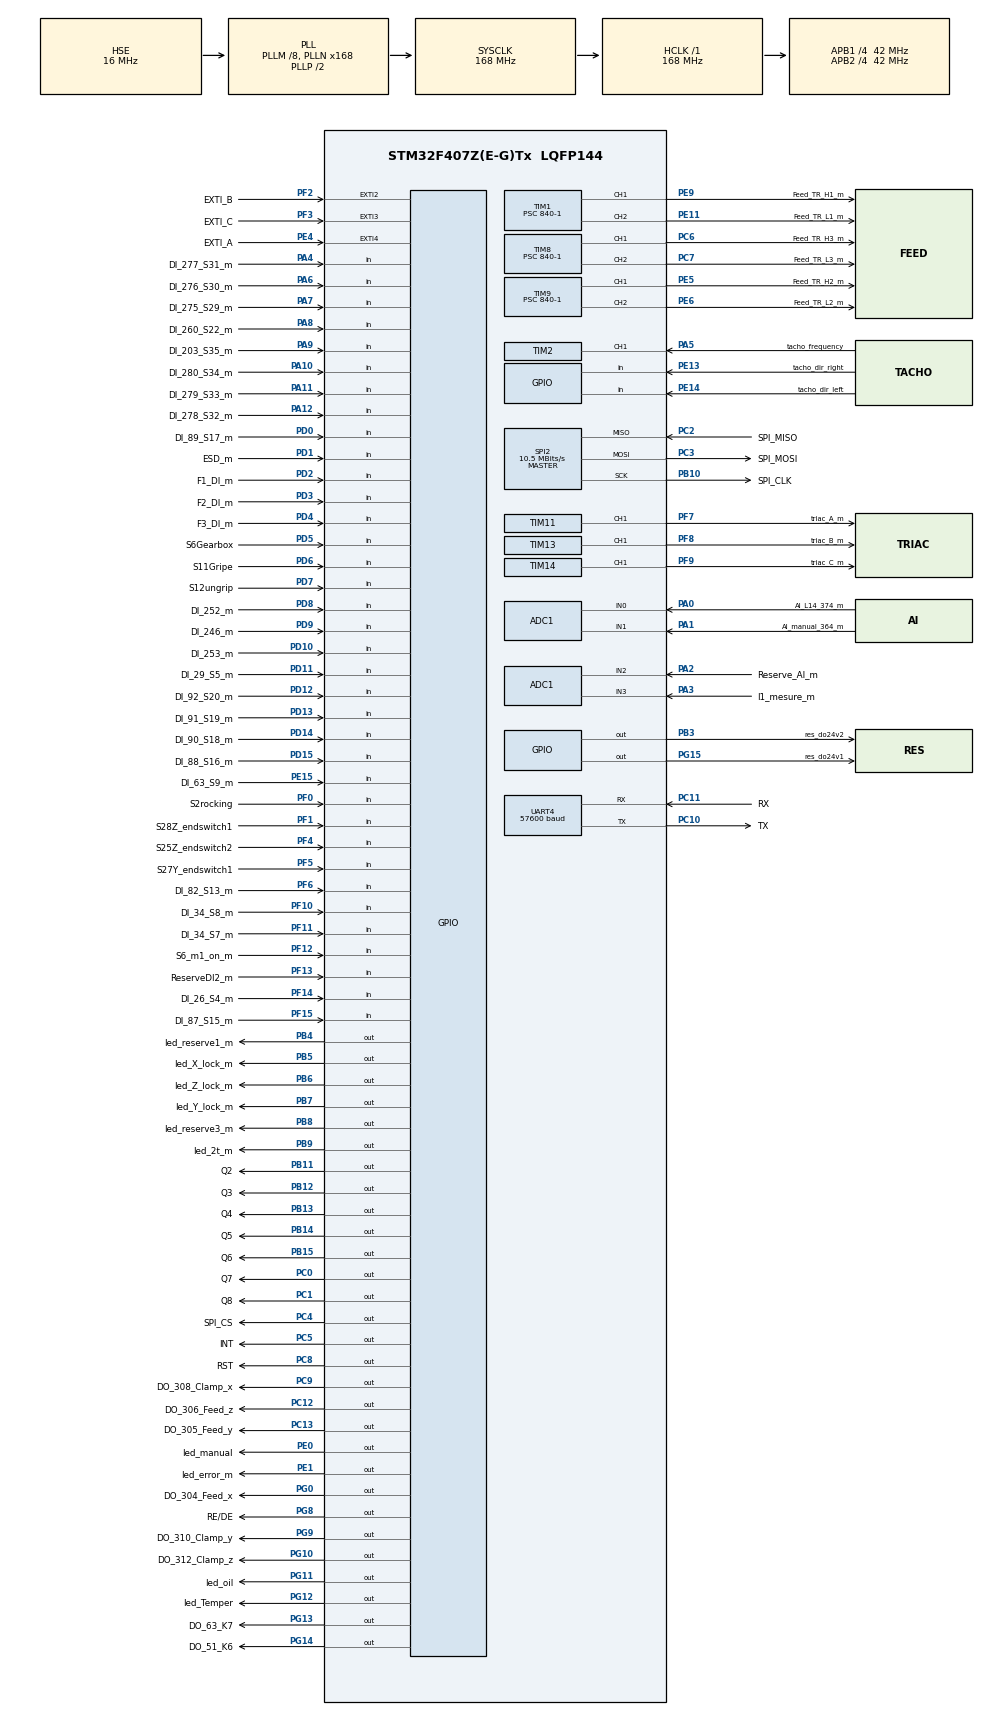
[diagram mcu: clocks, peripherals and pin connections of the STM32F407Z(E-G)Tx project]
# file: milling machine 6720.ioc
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ADC1.Channel-0\#ChannelRegularConversion=ADC_CHANNEL_0
ADC1.Channel-1\#ChannelRegularConversion=ADC_CHANNEL_0
ADC1.Channel-2\#ChannelRegularConversion=ADC_CHANNEL_0
ADC1.Channel-3\#ChannelRegularConversion=ADC_CHANNEL_0
ADC1.EOCSelection=ADC_EOC_SEQ_CONV
ADC1.InjNumberOfConversion=0
ADC1.NbrOfConversion=4
ADC1.NbrOfConversionFlag=1
ADC1.Rank-0\#ChannelRegularConversion=1
ADC1.Rank-1\#ChannelRegularConversion=2
ADC1.Rank-2\#ChannelRegularConversion=3
ADC1.Rank-3\#ChannelRegularConversion=4
ADC1.SamplingTime-0\#ChannelRegularConversion=ADC_SAMPLETIME_84CYCLES
ADC1.SamplingTime-1\#ChannelRegularConversion=ADC_SAMPLETIME_84CYCLES
ADC1.SamplingTime-2\#ChannelRegularConversion=ADC_SAMPLETIME_84CYCLES
ADC1.SamplingTime-3\#ChannelRegularConversion=ADC_SAMPLETIME_84CYCLES
ADC1.ScanConvMode=ENABLE
ADC1.master=1
Dma.ADC1.0.Direction=DMA_PERIPH_TO_MEMORY
Dma.ADC1.0.FIFOMode=DMA_FIFOMODE_DISABLE
Dma.ADC1.0.Instance=DMA2_Stream0
Dma.ADC1.0.MemDataAlignment=DMA_MDATAALIGN_HALFWORD
Dma.ADC1.0.MemInc=DMA_MINC_ENABLE
Dma.ADC1.0.Mode=DMA_NORMAL
Dma.ADC1.0.PeriphDataAlignment=DMA_PDATAALIGN_HALFWORD
Dma.ADC1.0.PeriphInc=DMA_PINC_DISABLE
Dma.ADC1.0.Priority=DMA_PRIORITY_LOW
Dma.Request0=ADC1
Dma.Request1=UART4_RX
Dma.Request2=UART4_TX
Dma.UART4_RX.1.Direction=DMA_PERIPH_TO_MEMORY
Dma.UART4_RX.1.FIFOMode=DMA_FIFOMODE_DISABLE
Dma.UART4_RX.1.Instance=DMA1_Stream2
Dma.UART4_RX.1.MemDataAlignment=DMA_MDATAALIGN_BYTE
Dma.UART4_RX.1.MemInc=DMA_MINC_ENABLE
Dma.UART4_RX.1.Mode=DMA_NORMAL
Dma.UART4_RX.1.PeriphDataAlignment=DMA_PDATAALIGN_BYTE
Dma.UART4_RX.1.PeriphInc=DMA_PINC_DISABLE
Dma.UART4_RX.1.Priority=DMA_PRIORITY_LOW
Dma.UART4_TX.2.Direction=DMA_MEMORY_TO_PERIPH
Dma.UART4_TX.2.FIFOMode=DMA_FIFOMODE_DISABLE
Dma.UART4_TX.2.Instance=DMA1_Stream4
Dma.UART4_TX.2.MemDataAlignment=DMA_MDATAALIGN_BYTE
Dma.UART4_TX.2.MemInc=DMA_MINC_ENABLE
Dma.UART4_TX.2.Mode=DMA_NORMAL
Dma.UART4_TX.2.PeriphDataAlignment=DMA_PDATAALIGN_BYTE
Dma.UART4_TX.2.PeriphInc=DMA_PINC_DISABLE
Dma.UART4_TX.2.Priority=DMA_PRIORITY_LOW
FREERTOS.Tasks01=MainTask,24,1024,StartMainTask,Default,NULL,Dynamic,NULL,NULL;Comunication,19,512,StartComunication,Default,NULL,Dynamic,NULL,NULL;feed,24,512,StartFeed,Default,NULL,Dynamic,NULL,NULL
IWDG.Prescaler=IWDG_PRESCALER_256
Mcu.Family=STM32F4
Mcu.Name=STM32F407Z(E-G)Tx
Mcu.Package=LQFP144
NVIC.DMA1_Stream2_IRQn=true\:5\:0\:false\:false\:true\:true\:false\:true\:true
NVIC.DMA1_Stream4_IRQn=true\:5\:0\:false\:false\:true\:true\:false\:true\:true
NVIC.DMA2_Stream0_IRQn=true\:5\:0\:false\:false\:true\:true\:false\:true\:true
NVIC.PriorityGroup=NVIC_PRIORITYGROUP_4
NVIC.TIM2_IRQn=true\:5\:0\:false\:false\:true\:true\:true\:true\:true
NVIC.TIM6_DAC_IRQn=true\:15\:0\:false\:false\:true\:false\:false\:true\:true
NVIC.TimeBase=TIM6_DAC_IRQn
NVIC.TimeBaseIP=TIM6
PA0-WKUP.GPIO_Label=AI_L14_374_m
PA0-WKUP.Signal=ADCx_IN0
PA1.GPIO_Label=AI_manual_364_m
PA1.Signal=ADCx_IN1
PA10.GPIO_Label=DI_280_S34_m
PA10.Signal=GPIO_Input
PA11.GPIO_Label=DI_279_S33_m
PA11.Signal=GPIO_Input
PA12.GPIO_Label=DI_278_S32_m
PA12.Signal=GPIO_Input
PA13.Mode=Serial_Wire
PA13.Signal=SYS_JTMS-SWDIO
PA14.Mode=Serial_Wire
PA14.Signal=SYS_JTCK-SWCLK
PA2.GPIO_Label=Reserve_AI_m
PA2.Signal=ADCx_IN2
PA3.GPIO_Label=I1_mesure_m
PA3.Signal=ADCx_IN3
PA4.GPIO_Label=DI_277_S31_m
PA4.Signal=GPIO_Input
PA5.GPIO_Label=tacho_frequency
PA5.Signal=S_TIM2_CH1_ETR
PA6.GPIO_Label=DI_276_S30_m
PA6.Signal=GPIO_Input
PA7.GPIO_Label=DI_275_S29_m
PA7.Signal=GPIO_Input
PA8.GPIO_Label=DI_260_S22_m
PA8.Signal=GPIO_Input
PA9.GPIO_Label=DI_203_S35_m
PA9.Signal=GPIO_Input
PB10.GPIO_Label=SPI_CLK
PB10.Mode=Full_Duplex_Master
PB10.Signal=SPI2_SCK
PB11.GPIO_Label=Q2
PB11.GPIO_ModeDefaultOutputPP=GPIO_MODE_OUTPUT_OD
PB11.GPIO_PuPd=GPIO_NOPULL
PB11.PinState=GPIO_PIN_SET
PB11.Signal=GPIO_Output
PB12.GPIO_Label=Q3
PB12.GPIO_ModeDefaultOutputPP=GPIO_MODE_OUTPUT_OD
PB12.GPIO_PuPd=GPIO_NOPULL
PB12.PinState=GPIO_PIN_SET
PB12.Signal=GPIO_Output
PB13.GPIO_Label=Q4
PB13.GPIO_ModeDefaultOutputPP=GPIO_MODE_OUTPUT_OD
PB13.GPIO_PuPd=GPIO_NOPULL
PB13.PinState=GPIO_PIN_SET
PB13.Signal=GPIO_Output
PB14.GPIO_Label=Q5
PB14.GPIO_ModeDefaultOutputPP=GPIO_MODE_OUTPUT_OD
PB14.GPIO_PuPd=GPIO_NOPULL
PB14.PinState=GPIO_PIN_SET
PB14.Signal=GPIO_Output
PB15.GPIO_Label=Q6
PB15.GPIO_ModeDefaultOutputPP=GPIO_MODE_OUTPUT_OD
PB15.GPIO_PuPd=GPIO_NOPULL
PB15.PinState=GPIO_PIN_SET
PB15.Signal=GPIO_Output
PB3.GPIO_Label=res_do24v2
PB3.GPIO_ModeDefaultOutputPP=GPIO_MODE_OUTPUT_OD
PB3.GPIO_PuPd=GPIO_NOPULL
PB3.PinState=GPIO_PIN_SET
PB3.Signal=GPIO_Output
PB4.GPIO_Label=led_reserve1_m
PB4.GPIO_ModeDefaultOutputPP=GPIO_MODE_OUTPUT_OD
PB4.GPIO_PuPd=GPIO_NOPULL
PB4.PinState=GPIO_PIN_SET
PB4.Signal=GPIO_Output
PB5.GPIO_Label=led_X_lock_m
PB5.GPIO_ModeDefaultOutputPP=GPIO_MODE_OUTPUT_OD
PB5.GPIO_PuPd=GPIO_NOPULL
PB5.PinState=GPIO_PIN_SET
PB5.Signal=GPIO_Output
PB6.GPIO_Label=led_Z_lock_m
PB6.GPIO_ModeDefaultOutputPP=GPIO_MODE_OUTPUT_OD
PB6.GPIO_PuPd=GPIO_NOPULL
PB6.PinState=GPIO_PIN_SET
PB6.Signal=GPIO_Output
PB7.GPIO_Label=led_Y_lock_m
PB7.GPIO_ModeDefaultOutputPP=GPIO_MODE_OUTPUT_OD
PB7.GPIO_PuPd=GPIO_NOPULL
PB7.PinState=GPIO_PIN_SET
PB7.Signal=GPIO_Output
PB8.GPIO_Label=led_reserve3_m
PB8.GPIO_ModeDefaultOutputPP=GPIO_MODE_OUTPUT_OD
PB8.GPIO_PuPd=GPIO_NOPULL
PB8.PinState=GPIO_PIN_SET
PB8.Signal=GPIO_Output
PB9.GPIO_Label=led_2t_m
PB9.GPIO_ModeDefaultOutputPP=GPIO_MODE_OUTPUT_OD
PB9.GPIO_PuPd=GPIO_NOPULL
PB9.PinState=GPIO_PIN_SET
PB9.Signal=GPIO_Output
PC0.GPIO_Label=Q7
PC0.GPIO_ModeDefaultOutputPP=GPIO_MODE_OUTPUT_OD
PC0.GPIO_PuPd=GPIO_NOPULL
PC0.PinState=GPIO_PIN_SET
PC0.Signal=GPIO_Output
PC1.GPIO_Label=Q8
PC1.GPIO_ModeDefaultOutputPP=GPIO_MODE_OUTPUT_OD
PC1.GPIO_PuPd=GPIO_NOPULL
PC1.PinState=GPIO_PIN_SET
PC1.Signal=GPIO_Output
PC10.GPIO_Label=TX
PC10.Mode=Asynchronous
PC10.Signal=UART4_TX
PC11.GPIO_Label=RX
PC11.Mode=Asynchronous
PC11.Signal=UART4_RX
PC12.GPIO_Label=DO_306_Feed_z
PC12.GPIO_ModeDefaultOutputPP=GPIO_MODE_OUTPUT_OD
PC12.GPIO_PuPd=GPIO_NOPULL
PC12.PinState=GPIO_PIN_SET
PC12.Signal=GPIO_Output
PC13-ANTI_TAMP.GPIO_Label=DO_305_Feed_y
PC13-ANTI_TAMP.GPIO_ModeDefaultOutputPP=GPIO_MODE_OUTPUT_OD
PC13-ANTI_TAMP.GPIO_PuPd=GPIO_NOPULL
PC13-ANTI_TAMP.PinState=GPIO_PIN_SET
PC13-ANTI_TAMP.Signal=GPIO_Output
PC2.GPIO_Label=SPI_MISO
PC2.Mode=Full_Duplex_Master
PC2.Signal=SPI2_MISO
PC3.GPIO_Label=SPI_MOSI
PC3.Mode=Full_Duplex_Master
PC3.Signal=SPI2_MOSI
PC4.GPIO_Label=SPI_CS
PC4.PinState=GPIO_PIN_RESET
PC4.Signal=GPIO_Output
PC5.GPIO_Label=INT
PC5.PinState=GPIO_PIN_RESET
PC5.Signal=GPIO_Output
PC6.GPIO_Label=Feed_TR_H3_m
PC6.Signal=S_TIM8_CH1
PC7.GPIO_Label=Feed_TR_L3_m
PC7.Signal=S_TIM8_CH2
PC8.GPIO_Label=RST
PC8.PinState=GPIO_PIN_RESET
PC8.Signal=GPIO_Output
PC9.GPIO_Label=DO_308_Clamp_x
PC9.GPIO_ModeDefaultOutputPP=GPIO_MODE_OUTPUT_OD
PC9.GPIO_PuPd=GPIO_NOPULL
PC9.PinState=GPIO_PIN_SET
PC9.Signal=GPIO_Output
PD0.GPIO_Label=DI_89_S17_m
PD0.Signal=GPIO_Input
PD1.GPIO_Label=ESD_m
PD1.Signal=GPIO_Input
PD10.GPIO_Label=DI_253_m
PD10.Signal=GPIO_Input
PD11.GPIO_Label=DI_29_S5_m
PD11.Signal=GPIO_Input
PD12.GPIO_Label=DI_92_S20_m
PD12.Signal=GPIO_Input
PD13.GPIO_Label=DI_91_S19_m
PD13.Signal=GPIO_Input
PD14.GPIO_Label=DI_90_S18_m
PD14.Signal=GPIO_Input
PD15.GPIO_Label=DI_88_S16_m
PD15.Signal=GPIO_Input
PD2.GPIO_Label=F1_DI_m
PD2.Signal=GPIO_Input
PD3.GPIO_Label=F2_DI_m
PD3.Signal=GPIO_Input
PD4.GPIO_Label=F3_DI_m
PD4.Signal=GPIO_Input
PD5.GPIO_Label=S6Gearbox
PD5.Signal=GPIO_Input
PD6.GPIO_Label=S11Gripe
PD6.Signal=GPIO_Input
PD7.GPIO_Label=S12ungrip
PD7.GPIO_PuPd=GPIO_NOPULL
PD7.Signal=GPIO_Input
PD8.GPIO_Label=DI_252_m
PD8.Signal=GPIO_Input
PD9.GPIO_Label=DI_246_m
PD9.Signal=GPIO_Input
PE0.GPIO_Label=led_manual
PE0.GPIO_ModeDefaultOutputPP=GPIO_MODE_OUTPUT_OD
PE0.PinState=GPIO_PIN_SET
PE0.Signal=GPIO_Output
PE1.GPIO_Label=led_error_m
PE1.GPIO_ModeDefaultOutputPP=GPIO_MODE_OUTPUT_OD
PE1.GPIO_PuPd=GPIO_NOPULL
PE1.PinState=GPIO_PIN_SET
PE1.Signal=GPIO_Output
PE11.GPIO_Label=Feed_TR_L1_m
PE11.Signal=S_TIM1_CH2
PE13.GPIO_Label=tacho_dir_right
PE13.Signal=GPIO_Input
PE14.GPIO_Label=tacho_dir_left
PE14.Signal=GPIO_Input
PE15.GPIO_Label=DI_63_S9_m
PE15.Signal=GPIO_Input
PE4.GPIO_Label=EXTI_A
PE4.Signal=GPXTI4
PE5.GPIO_Label=Feed_TR_H2_m
PE5.Signal=S_TIM9_CH1
PE6.GPIO_Label=Feed_TR_L2_m
PE6.Signal=S_TIM9_CH2
PE9.GPIO_Label=Feed_TR_H1_m
PE9.Signal=S_TIM1_CH1
PF0.GPIO_Label=S2rocking
PF0.Signal=GPIO_Input
PF1.GPIO_Label=S28Z_endswitch1
PF1.Signal=GPIO_Input
PF10.GPIO_Label=DI_34_S8_m
PF10.Signal=GPIO_Input
PF11.GPIO_Label=DI_34_S7_m
PF11.Signal=GPIO_Input
PF12.GPIO_Label=S6_m1_on_m
PF12.Signal=GPIO_Input
PF13.GPIO_Label=ReserveDI2_m
PF13.Signal=GPIO_Input
PF14.GPIO_Label=DI_26_S4_m
PF14.Signal=GPIO_Input
PF15.GPIO_Label=DI_87_S15_m
PF15.Signal=GPIO_Input
PF2.GPIO_Label=EXTI_B
PF2.GPIO_ModeDefaultEXTI=GPIO_MODE_IT_RISING_FALLING
PF2.Signal=GPXTI2
PF3.GPIO_Label=EXTI_C
PF3.GPIO_ModeDefaultEXTI=GPIO_MODE_IT_RISING_FALLING
PF3.Signal=GPXTI3
PF4.GPIO_Label=S25Z_endswitch2
PF4.Signal=GPIO_Input
PF5.GPIO_Label=S27Y_endswitch1
PF5.Signal=GPIO_Input
PF6.GPIO_Label=DI_82_S13_m
PF6.Signal=GPIO_Input
PF7.GPIO_Label=triac_A_m
PF7.Signal=S_TIM11_CH1
PF8.GPIO_Label=triac_B_m
PF8.Signal=S_TIM13_CH1
PF9.GPIO_Label=triac_C_m
PF9.Signal=S_TIM14_CH1
PG0.GPIO_Label=DO_304_Feed_x
PG0.GPIO_ModeDefaultOutputPP=GPIO_MODE_OUTPUT_OD
PG0.GPIO_PuPd=GPIO_NOPULL
PG0.PinState=GPIO_PIN_SET
PG0.Signal=GPIO_Output
PG10.GPIO_Label=DO_312_Clamp_z
PG10.GPIO_ModeDefaultOutputPP=GPIO_MODE_OUTPUT_OD
PG10.GPIO_PuPd=GPIO_NOPULL
PG10.PinState=GPIO_PIN_SET
PG10.Signal=GPIO_Output
PG11.GPIO_Label=led_oil
PG11.GPIO_ModeDefaultOutputPP=GPIO_MODE_OUTPUT_OD
PG11.GPIO_PuPd=GPIO_NOPULL
PG11.PinState=GPIO_PIN_SET
PG11.Signal=GPIO_Output
PG12.GPIO_Label=led_Temper
PG12.GPIO_ModeDefaultOutputPP=GPIO_MODE_OUTPUT_OD
PG12.GPIO_PuPd=GPIO_NOPULL
PG12.PinState=GPIO_PIN_SET
PG12.Signal=GPIO_Output
PG13.GPIO_Label=DO_63_K7
PG13.GPIO_ModeDefaultOutputPP=GPIO_MODE_OUTPUT_OD
PG13.GPIO_PuPd=GPIO_NOPULL
PG13.PinState=GPIO_PIN_SET
PG13.Signal=GPIO_Output
PG14.GPIO_Label=DO_51_K6
PG14.GPIO_ModeDefaultOutputPP=GPIO_MODE_OUTPUT_OD
PG14.GPIO_PuPd=GPIO_NOPULL
PG14.PinState=GPIO_PIN_SET
PG14.Signal=GPIO_Output
PG15.GPIO_Label=res_do24v1
PG15.GPIO_ModeDefaultOutputPP=GPIO_MODE_OUTPUT_OD
PG15.GPIO_PuPd=GPIO_NOPULL
PG15.PinState=GPIO_PIN_SET
PG15.Signal=GPIO_Output
PG8.GPIO_Label=RE/DE
PG8.PinState=GPIO_PIN_RESET
PG8.Signal=GPIO_Output
PG9.GPIO_Label=DO_310_Clamp_y
PG9.GPIO_ModeDefaultOutputPP=GPIO_MODE_OUTPUT_OD
PG9.GPIO_PuPd=GPIO_NOPULL
PG9.PinState=GPIO_PIN_SET
PG9.Signal=GPIO_Output
PH0-OSC_IN.Mode=HSE-External-Oscillator
PH0-OSC_IN.Signal=RCC_OSC_IN
PH1-OSC_OUT.Mode=HSE-External-Oscillator
PH1-OSC_OUT.Signal=RCC_OSC_OUT
ProjectManager.HeapSize=0x200
ProjectManager.StackSize=0x400
ProjectManager.TargetToolchain=EWARM V8
RCC.48MHZClocksFreq_Value=84000000
RCC.AHBFreq_Value=168000000
RCC.APB1CLKDivider=RCC_HCLK_DIV4
RCC.APB1Freq_Value=42000000
RCC.APB1TimFreq_Value=84000000
RCC.APB2CLKDivider=RCC_HCLK_DIV4
RCC.APB2Freq_Value=42000000
RCC.APB2TimFreq_Value=84000000
RCC.CortexFreq_Value=168000000
RCC.HCLKFreq_Value=168000000
RCC.HSE_VALUE=16000000
RCC.HSI_VALUE=16000000
RCC.LSE_VALUE=32768
RCC.PLLM=8
RCC.PLLN=168
RCC.PLLSourceVirtual=RCC_PLLSOURCE_HSE
RCC.SYSCLKFreq_VALUE=168000000
RCC.SYSCLKSource=RCC_SYSCLKSOURCE_PLLCLK
RCC.VCOOutputFreq_Value=336000000
SH.ADCx_IN0.0=ADC1_IN0,IN0
SH.ADCx_IN1.0=ADC1_IN1,IN1
SH.ADCx_IN2.0=ADC1_IN2,IN2
SH.ADCx_IN3.0=ADC1_IN3,IN3
SH.S_TIM11_CH1.0=TIM11_CH1,PWM Generation1 CH1
SH.S_TIM13_CH1.0=TIM13_CH1,PWM Generation1 CH1
SH.S_TIM14_CH1.0=TIM14_CH1,PWM Generation1 CH1
SH.S_TIM1_CH1.0=TIM1_CH1,PWM Generation1 CH1
SH.S_TIM1_CH2.0=TIM1_CH2,PWM Generation2 CH2
SH.S_TIM2_CH1_ETR.0=TIM2_CH1,Input_Capture1_from_TI1
SH.S_TIM8_CH1.0=TIM8_CH1,PWM Generation1 CH1
SH.S_TIM8_CH2.0=TIM8_CH2,PWM Generation2 CH2
SH.S_TIM9_CH1.0=TIM9_CH1,PWM Generation1 CH1
SH.S_TIM9_CH2.0=TIM9_CH2,PWM Generation2 CH2
SPI2.BaudRatePrescaler=SPI_BAUDRATEPRESCALER_4
SPI2.CalculateBaudRate=10.5 MBits/s
SPI2.Direction=SPI_DIRECTION_2LINES
SPI2.Mode=SPI_MODE_MASTER
SPI2.VirtualType=VM_MASTER
TIM1.Channel-PWM\ Generation1\ CH1=TIM_CHANNEL_1
TIM1.Channel-PWM\ Generation2\ CH2=TIM_CHANNEL_2
TIM1.OCIdleState_1=TIM_OCIDLESTATE_RESET
TIM1.OCIdleState_2=TIM_OCIDLESTATE_RESET
TIM1.OCMode_PWM-PWM\ Generation1\ CH1=TIM_OCMODE_PWM1
TIM1.OCMode_PWM-PWM\ Generation2\ CH2=TIM_OCMODE_PWM1
TIM1.Period=1999
TIM1.Prescaler=840-1
TIM11.Channel=TIM_CHANNEL_1
TIM11.OCMode_PWM=TIM_OCMODE_PWM2
TIM11.Period=999
TIM11.Prescaler=840-1
TIM13.Channel=TIM_CHANNEL_1
TIM13.OCMode_PWM=TIM_OCMODE_PWM2
TIM13.Period=999
TIM13.Prescaler=840-1
TIM14.Channel=TIM_CHANNEL_1
TIM14.OCMode_PWM=TIM_OCMODE_PWM2
TIM14.Period=999
TIM14.Prescaler=840-1
TIM2.Channel-Input_Capture1_from_TI1=TIM_CHANNEL_1
TIM2.ICFilter_CH1=1
TIM2.ICPolarity_CH1=TIM_INPUTCHANNELPOLARITY_FALLING
TIM2.Prescaler=8400-1
TIM3.Prescaler=65534
TIM8.Channel-PWM\ Generation1\ CH1=TIM_CHANNEL_1
TIM8.Channel-PWM\ Generation2\ CH2=TIM_CHANNEL_2
TIM8.OCIdleState_1=TIM_OCIDLESTATE_RESET
TIM8.OCIdleState_2=TIM_OCIDLESTATE_RESET
TIM8.OCMode_PWM-PWM\ Generation1\ CH1=TIM_OCMODE_PWM1
TIM8.OCMode_PWM-PWM\ Generation2\ CH2=TIM_OCMODE_PWM1
TIM8.Period=1999
TIM8.Prescaler=840-1
TIM9.Channel-PWM\ Generation1\ CH1=TIM_CHANNEL_1
TIM9.Channel-PWM\ Generation2\ CH2=TIM_CHANNEL_2
TIM9.OCMode_PWM-PWM\ Generation1\ CH1=TIM_OCMODE_PWM1
TIM9.OCMode_PWM-PWM\ Generation2\ CH2=TIM_OCMODE_PWM1
TIM9.OCPolarity_1=TIM_OCPOLARITY_HIGH
TIM9.OCPolarity_2=TIM_OCPOLARITY_HIGH
TIM9.Period=1999
TIM9.Prescaler=840-1
UART4.BaudRate=57600
UART4.Parity=PARITY_EVEN
UART4.StopBits=UART_STOPBITS_2
UART4.VirtualMode=Asynchronous
VP_FREERTOS_VS_CMSIS_V2.Mode=CMSIS_V2
VP_IWDG_VS_IWDG.Mode=IWDG_Activate
VP_SYS_VS_tim6.Mode=TIM6
VP_TIM11_VS_ClockSourceINT.Mode=Enable_Timer
VP_TIM11_VS_OPM.Mode=OPM_bit
VP_TIM13_VS_ClockSourceINT.Mode=Enable_Timer
VP_TIM13_VS_OPM.Mode=OPM_bit
VP_TIM14_VS_ClockSourceINT.Mode=Enable_Timer
VP_TIM14_VS_OPM.Mode=OPM_bit
VP_TIM1_VS_OPM.Mode=OPM_bit
VP_TIM2_VS_ClockSourceINT.Mode=Internal
VP_TIM3_VS_ClockSourceINT.Mode=Internal
VP_TIM8_VS_OPM.Mode=OPM_bit
VP_TIM9_VS_OPM.Mode=OPM_bit
board=custom

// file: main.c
/* USER CODE BEGIN Header */
/**
  ******************************************************************************
  * @file           : main.c
  * @brief          : Main program body
  ******************************************************************************
  * @attention
  *
  * Copyright (c) 2023 STMicroelectronics.
  * All rights reserved.
  *
  * This software is licensed under terms that can be found in the LICENSE file
  * in the root directory of this software component.
  * If no LICENSE file comes with this software, it is provided AS-IS.
  *
  ******************************************************************************
  */
/* USER CODE END Header */
#include "main.h"
#include "cmsis_os.h"

/* USER CODE BEGIN Includes */
#if Comissioning==1
#include "stdio.h"
#endif
/* USER CODE END Includes */

ADC_HandleTypeDef hadc1;
DMA_HandleTypeDef hdma_adc1;

IWDG_HandleTypeDef hiwdg;

SPI_HandleTypeDef hspi2;

TIM_HandleTypeDef htim1;
TIM_HandleTypeDef htim2;
TIM_HandleTypeDef htim3;
TIM_HandleTypeDef htim8;
TIM_HandleTypeDef htim9;
TIM_HandleTypeDef htim11;
TIM_HandleTypeDef htim13;
TIM_HandleTypeDef htim14;

UART_HandleTypeDef huart4;
DMA_HandleTypeDef hdma_uart4_rx;
DMA_HandleTypeDef hdma_uart4_tx;

/* Definitions for MainTask */
osThreadId_t MainTaskHandle;
const osThreadAttr_t MainTask_attributes = {
  .name = "MainTask",
  .stack_size = 1024 * 4,
  .priority = (osPriority_t) osPriorityNormal,
};
/* Definitions for Comunication */
osThreadId_t ComunicationHandle;
const osThreadAttr_t Comunication_attributes = {
  .name = "Comunication",
  .stack_size = 512 * 4,
  .priority = (osPriority_t) osPriorityBelowNormal3,
};
/* Definitions for feed */
osThreadId_t feedHandle;
const osThreadAttr_t feed_attributes = {
  .name = "feed",
  .stack_size = 512 * 4,
  .priority = (osPriority_t) osPriorityNormal,
};
/* USER CODE BEGIN PV */
//--------my global variables----------//
volatile uint16_t dma[4];
uint8_t error_my=0, feed_motion=0, M1_motion=0, polyarity,first_intrrupt=1; // 0-off 1-rigt, 2-left, 3-Rocking, 4-brake active
uint16_t Time_b=0,Time_c=0, feed_speed_sp=0, I_M4=0;
uint16_t PWM_M1=0; //0-1000
uint16_t PWM_M4=0;//1000 RPS
uint32_t Freq_TIM2=10000;  //10000 is one rpm/sec or 600000 is one rpm/min
//========================================//
/* USER CODE END PV */

void SystemClock_Config(void);
static void MX_GPIO_Init(void);
static void MX_DMA_Init(void);
static void MX_IWDG_Init(void);
static void MX_TIM1_Init(void);
static void MX_TIM8_Init(void);
static void MX_TIM9_Init(void);
static void MX_UART4_Init(void);
static void MX_ADC1_Init(void);
static void MX_TIM11_Init(void);
static void MX_TIM13_Init(void);
static void MX_TIM14_Init(void);
static void MX_SPI2_Init(void);
static void MX_TIM2_Init(void);
static void MX_TIM3_Init(void);
void StartMainTask(void *argument);
void StartComunication(void *argument);
void StartFeed(void *argument);

int main(void)
{

  /* MCU Configuration--------------------------------------------------------*/

  /* Reset of all peripherals, Initializes the Flash interface and the Systick. */
  HAL_Init();

  /* Configure the system clock */
  SystemClock_Config();

  /* Initialize all configured peripherals */
  MX_GPIO_Init();
  MX_DMA_Init();
  MX_IWDG_Init();
  MX_TIM1_Init();
  MX_TIM8_Init();
  MX_TIM9_Init();
  MX_UART4_Init();
  MX_ADC1_Init();
  MX_TIM11_Init();
  MX_TIM13_Init();
  MX_TIM14_Init();
  MX_SPI2_Init();
  MX_TIM2_Init();
  MX_TIM3_Init();

  /* Init scheduler */
  osKernelInitialize();

  /* Create the thread(s) */
  /* creation of MainTask */
  MainTaskHandle = osThreadNew(StartMainTask, NULL, &MainTask_attributes);

  /* creation of Comunication */
  ComunicationHandle = osThreadNew(StartComunication, NULL, &Comunication_attributes);

  /* creation of feed */
  feedHandle = osThreadNew(StartFeed, NULL, &feed_attributes);

  /* Start scheduler */
  osKernelStart();

  /* We should never get here as control is now taken by the scheduler */
  /* Infinite loop */
  while (1)
  {

  }
}

void SystemClock_Config(void)
{
  RCC_OscInitTypeDef RCC_OscInitStruct = {0};
  RCC_ClkInitTypeDef RCC_ClkInitStruct = {0};

  /** Configure the main internal regulator output voltage
  */
  __HAL_RCC_PWR_CLK_ENABLE();
  __HAL_PWR_VOLTAGESCALING_CONFIG(PWR_REGULATOR_VOLTAGE_SCALE1);

  /** Initializes the RCC Oscillators according to the specified parameters
  * in the RCC_OscInitTypeDef structure.
  */
  RCC_OscInitStruct.OscillatorType = RCC_OSCILLATORTYPE_LSI|RCC_OSCILLATORTYPE_HSE;
  RCC_OscInitStruct.HSEState = RCC_HSE_ON;
  RCC_OscInitStruct.LSIState = RCC_LSI_ON;
  RCC_OscInitStruct.PLL.PLLState = RCC_PLL_ON;
  RCC_OscInitStruct.PLL.PLLSource = RCC_PLLSOURCE_HSE;
  RCC_OscInitStruct.PLL.PLLM = 8;
  RCC_OscInitStruct.PLL.PLLN = 168;
  RCC_OscInitStruct.PLL.PLLP = RCC_PLLP_DIV2;
  RCC_OscInitStruct.PLL.PLLQ = 4;
  if (HAL_RCC_OscConfig(&RCC_OscInitStruct) != HAL_OK)
  {
    Error_Handler();
  }

  /** Initializes the CPU, AHB and APB buses clocks
  */
  RCC_ClkInitStruct.ClockType = RCC_CLOCKTYPE_HCLK|RCC_CLOCKTYPE_SYSCLK
                              |RCC_CLOCKTYPE_PCLK1|RCC_CLOCKTYPE_PCLK2;
  RCC_ClkInitStruct.SYSCLKSource = RCC_SYSCLKSOURCE_PLLCLK;
  RCC_ClkInitStruct.AHBCLKDivider = RCC_SYSCLK_DIV1;
  RCC_ClkInitStruct.APB1CLKDivider = RCC_HCLK_DIV4;
  RCC_ClkInitStruct.APB2CLKDivider = RCC_HCLK_DIV4;

  if (HAL_RCC_ClockConfig(&RCC_ClkInitStruct, FLASH_LATENCY_5) != HAL_OK)
  {
    Error_Handler();
  }
}

static void MX_ADC1_Init(void)
{

  ADC_ChannelConfTypeDef sConfig = {0};

  /** Configure the global features of the ADC (Clock, Resolution, Data Alignment and number of conversion)
  */
  hadc1.Instance = ADC1;
  hadc1.Init.ClockPrescaler = ADC_CLOCK_SYNC_PCLK_DIV2;
  hadc1.Init.Resolution = ADC_RESOLUTION_12B;
  hadc1.Init.ScanConvMode = ENABLE;
  hadc1.Init.ContinuousConvMode = DISABLE;
  hadc1.Init.DiscontinuousConvMode = DISABLE;
  hadc1.Init.ExternalTrigConvEdge = ADC_EXTERNALTRIGCONVEDGE_NONE;
  hadc1.Init.ExternalTrigConv = ADC_SOFTWARE_START;
  hadc1.Init.DataAlign = ADC_DATAALIGN_RIGHT;
  hadc1.Init.NbrOfConversion = 4;
  hadc1.Init.DMAContinuousRequests = DISABLE;
  hadc1.Init.EOCSelection = ADC_EOC_SEQ_CONV;
  if (HAL_ADC_Init(&hadc1) != HAL_OK)
  {
    Error_Handler();
  }

  /** Configure for the selected ADC regular channel its corresponding rank in the sequencer and its sample time.
  */
  sConfig.Channel = ADC_CHANNEL_0;
  sConfig.Rank = 1;
  sConfig.SamplingTime = ADC_SAMPLETIME_84CYCLES;
  if (HAL_ADC_ConfigChannel(&hadc1, &sConfig) != HAL_OK)
  {
    Error_Handler();
  }

  /** Configure for the selected ADC regular channel its corresponding rank in the sequencer and its sample time.
  */
  sConfig.Rank = 2;
  if (HAL_ADC_ConfigChannel(&hadc1, &sConfig) != HAL_OK)
  {
    Error_Handler();
  }

  /** Configure for the selected ADC regular channel its corresponding rank in the sequencer and its sample time.
  */
  sConfig.Rank = 3;
  if (HAL_ADC_ConfigChannel(&hadc1, &sConfig) != HAL_OK)
  {
    Error_Handler();
  }

  /** Configure for the selected ADC regular channel its corresponding rank in the sequencer and its sample time.
  */
  sConfig.Rank = 4;
  if (HAL_ADC_ConfigChannel(&hadc1, &sConfig) != HAL_OK)
  {
    Error_Handler();
  }

}

static void MX_IWDG_Init(void)
{

  hiwdg.Instance = IWDG;
  hiwdg.Init.Prescaler = IWDG_PRESCALER_256;
  hiwdg.Init.Reload = 4095;
  if (HAL_IWDG_Init(&hiwdg) != HAL_OK)
  {
    Error_Handler();
  }

}

static void MX_SPI2_Init(void)
{

  /* SPI2 parameter configuration*/
  hspi2.Instance = SPI2;
  hspi2.Init.Mode = SPI_MODE_MASTER;
  hspi2.Init.Direction = SPI_DIRECTION_2LINES;
  hspi2.Init.DataSize = SPI_DATASIZE_8BIT;
  hspi2.Init.CLKPolarity = SPI_POLARITY_LOW;
  hspi2.Init.CLKPhase = SPI_PHASE_1EDGE;
  hspi2.Init.NSS = SPI_NSS_SOFT;
  hspi2.Init.BaudRatePrescaler = SPI_BAUDRATEPRESCALER_4;
  hspi2.Init.FirstBit = SPI_FIRSTBIT_MSB;
  hspi2.Init.TIMode = SPI_TIMODE_DISABLE;
  hspi2.Init.CRCCalculation = SPI_CRCCALCULATION_DISABLE;
  hspi2.Init.CRCPolynomial = 10;
  if (HAL_SPI_Init(&hspi2) != HAL_OK)
  {
    Error_Handler();
  }

}

static void MX_TIM1_Init(void)
{

  TIM_MasterConfigTypeDef sMasterConfig = {0};
  TIM_OC_InitTypeDef sConfigOC = {0};
  TIM_BreakDeadTimeConfigTypeDef sBreakDeadTimeConfig = {0};

  htim1.Instance = TIM1;
  htim1.Init.Prescaler = 840-1;
  htim1.Init.CounterMode = TIM_COUNTERMODE_UP;
  htim1.Init.Period = 1999;
  htim1.Init.ClockDivision = TIM_CLOCKDIVISION_DIV1;
  htim1.Init.RepetitionCounter = 0;
  htim1.Init.AutoReloadPreload = TIM_AUTORELOAD_PRELOAD_DISABLE;
  if (HAL_TIM_PWM_Init(&htim1) != HAL_OK)
  {
    Error_Handler();
  }
  if (HAL_TIM_OnePulse_Init(&htim1, TIM_OPMODE_SINGLE) != HAL_OK)
  {
    Error_Handler();
  }
  sMasterConfig.MasterOutputTrigger = TIM_TRGO_RESET;
  sMasterConfig.MasterSlaveMode = TIM_MASTERSLAVEMODE_DISABLE;
  if (HAL_TIMEx_MasterConfigSynchronization(&htim1, &sMasterConfig) != HAL_OK)
  {
    Error_Handler();
  }
  sConfigOC.OCMode = TIM_OCMODE_PWM1;
  sConfigOC.Pulse = 0;
  sConfigOC.OCPolarity = TIM_OCPOLARITY_HIGH;
  sConfigOC.OCNPolarity = TIM_OCNPOLARITY_HIGH;
  sConfigOC.OCFastMode = TIM_OCFAST_DISABLE;
  sConfigOC.OCIdleState = TIM_OCIDLESTATE_RESET;
  sConfigOC.OCNIdleState = TIM_OCNIDLESTATE_RESET;
  if (HAL_TIM_PWM_ConfigChannel(&htim1, &sConfigOC, TIM_CHANNEL_1) != HAL_OK)
  {
    Error_Handler();
  }
  if (HAL_TIM_PWM_ConfigChannel(&htim1, &sConfigOC, TIM_CHANNEL_2) != HAL_OK)
  {
    Error_Handler();
  }
  sBreakDeadTimeConfig.OffStateRunMode = TIM_OSSR_DISABLE;
  sBreakDeadTimeConfig.OffStateIDLEMode = TIM_OSSI_DISABLE;
  sBreakDeadTimeConfig.LockLevel = TIM_LOCKLEVEL_OFF;
  sBreakDeadTimeConfig.DeadTime = 0;
  sBreakDeadTimeConfig.BreakState = TIM_BREAK_DISABLE;
  sBreakDeadTimeConfig.BreakPolarity = TIM_BREAKPOLARITY_HIGH;
  sBreakDeadTimeConfig.AutomaticOutput = TIM_AUTOMATICOUTPUT_DISABLE;
  if (HAL_TIMEx_ConfigBreakDeadTime(&htim1, &sBreakDeadTimeConfig) != HAL_OK)
  {
    Error_Handler();
  }
  HAL_TIM_MspPostInit(&htim1);

}

static void MX_TIM2_Init(void)
{

  TIM_ClockConfigTypeDef sClockSourceConfig = {0};
  TIM_MasterConfigTypeDef sMasterConfig = {0};
  TIM_IC_InitTypeDef sConfigIC = {0};

  htim2.Instance = TIM2;
  htim2.Init.Prescaler = 8400-1;
  htim2.Init.CounterMode = TIM_COUNTERMODE_UP;
  htim2.Init.Period = 4294967295;
  htim2.Init.ClockDivision = TIM_CLOCKDIVISION_DIV1;
  htim2.Init.AutoReloadPreload = TIM_AUTORELOAD_PRELOAD_DISABLE;
  if (HAL_TIM_Base_Init(&htim2) != HAL_OK)
  {
    Error_Handler();
  }
  sClockSourceConfig.ClockSource = TIM_CLOCKSOURCE_INTERNAL;
  if (HAL_TIM_ConfigClockSource(&htim2, &sClockSourceConfig) != HAL_OK)
  {
    Error_Handler();
  }
  if (HAL_TIM_IC_Init(&htim2) != HAL_OK)
  {
    Error_Handler();
  }
  sMasterConfig.MasterOutputTrigger = TIM_TRGO_RESET;
  sMasterConfig.MasterSlaveMode = TIM_MASTERSLAVEMODE_DISABLE;
  if (HAL_TIMEx_MasterConfigSynchronization(&htim2, &sMasterConfig) != HAL_OK)
  {
    Error_Handler();
  }
  sConfigIC.ICPolarity = TIM_INPUTCHANNELPOLARITY_FALLING;
  sConfigIC.ICSelection = TIM_ICSELECTION_DIRECTTI;
  sConfigIC.ICPrescaler = TIM_ICPSC_DIV1;
  sConfigIC.ICFilter = 1;
  if (HAL_TIM_IC_ConfigChannel(&htim2, &sConfigIC, TIM_CHANNEL_1) != HAL_OK)
  {
    Error_Handler();
  }

}

static void MX_TIM3_Init(void)
{

  TIM_ClockConfigTypeDef sClockSourceConfig = {0};
  TIM_MasterConfigTypeDef sMasterConfig = {0};

  htim3.Instance = TIM3;
  htim3.Init.Prescaler = 65534;
  htim3.Init.CounterMode = TIM_COUNTERMODE_UP;
  htim3.Init.Period = 65535;
  htim3.Init.ClockDivision = TIM_CLOCKDIVISION_DIV1;
  htim3.Init.AutoReloadPreload = TIM_AUTORELOAD_PRELOAD_DISABLE;
  if (HAL_TIM_Base_Init(&htim3) != HAL_OK)
  {
    Error_Handler();
  }
  sClockSourceConfig.ClockSource = TIM_CLOCKSOURCE_INTERNAL;
  if (HAL_TIM_ConfigClockSource(&htim3, &sClockSourceConfig) != HAL_OK)
  {
    Error_Handler();
  }
  sMasterConfig.MasterOutputTrigger = TIM_TRGO_RESET;
  sMasterConfig.MasterSlaveMode = TIM_MASTERSLAVEMODE_DISABLE;
  if (HAL_TIMEx_MasterConfigSynchronization(&htim3, &sMasterConfig) != HAL_OK)
  {
    Error_Handler();
  }

}

static void MX_TIM8_Init(void)
{

  TIM_MasterConfigTypeDef sMasterConfig = {0};
  TIM_OC_InitTypeDef sConfigOC = {0};
  TIM_BreakDeadTimeConfigTypeDef sBreakDeadTimeConfig = {0};

  htim8.Instance = TIM8;
  htim8.Init.Prescaler = 840-1;
  htim8.Init.CounterMode = TIM_COUNTERMODE_UP;
  htim8.Init.Period = 1999;
  htim8.Init.ClockDivision = TIM_CLOCKDIVISION_DIV1;
  htim8.Init.RepetitionCounter = 0;
  htim8.Init.AutoReloadPreload = TIM_AUTORELOAD_PRELOAD_DISABLE;
  if (HAL_TIM_PWM_Init(&htim8) != HAL_OK)
  {
    Error_Handler();
  }
  if (HAL_TIM_OnePulse_Init(&htim8, TIM_OPMODE_SINGLE) != HAL_OK)
  {
    Error_Handler();
  }
  sMasterConfig.MasterOutputTrigger = TIM_TRGO_RESET;
  sMasterConfig.MasterSlaveMode = TIM_MASTERSLAVEMODE_DISABLE;
  if (HAL_TIMEx_MasterConfigSynchronization(&htim8, &sMasterConfig) != HAL_OK)
  {
    Error_Handler();
  }
  sConfigOC.OCMode = TIM_OCMODE_PWM1;
  sConfigOC.Pulse = 0;
  sConfigOC.OCPolarity = TIM_OCPOLARITY_HIGH;
  sConfigOC.OCNPolarity = TIM_OCNPOLARITY_HIGH;
  sConfigOC.OCFastMode = TIM_OCFAST_DISABLE;
  sConfigOC.OCIdleState = TIM_OCIDLESTATE_RESET;
  sConfigOC.OCNIdleState = TIM_OCNIDLESTATE_RESET;
  if (HAL_TIM_PWM_ConfigChannel(&htim8, &sConfigOC, TIM_CHANNEL_1) != HAL_OK)
  {
    Error_Handler();
  }
  if (HAL_TIM_PWM_ConfigChannel(&htim8, &sConfigOC, TIM_CHANNEL_2) != HAL_OK)
  {
    Error_Handler();
  }
  sBreakDeadTimeConfig.OffStateRunMode = TIM_OSSR_DISABLE;
  sBreakDeadTimeConfig.OffStateIDLEMode = TIM_OSSI_DISABLE;
  sBreakDeadTimeConfig.LockLevel = TIM_LOCKLEVEL_OFF;
  sBreakDeadTimeConfig.DeadTime = 0;
  sBreakDeadTimeConfig.BreakState = TIM_BREAK_DISABLE;
  sBreakDeadTimeConfig.BreakPolarity = TIM_BREAKPOLARITY_HIGH;
  sBreakDeadTimeConfig.AutomaticOutput = TIM_AUTOMATICOUTPUT_DISABLE;
  if (HAL_TIMEx_ConfigBreakDeadTime(&htim8, &sBreakDeadTimeConfig) != HAL_OK)
  {
    Error_Handler();
  }
  HAL_TIM_MspPostInit(&htim8);

}

static void MX_TIM9_Init(void)
{

  TIM_OC_InitTypeDef sConfigOC = {0};

  htim9.Instance = TIM9;
  htim9.Init.Prescaler = 840-1;
  htim9.Init.CounterMode = TIM_COUNTERMODE_UP;
  htim9.Init.Period = 1999;
  htim9.Init.ClockDivision = TIM_CLOCKDIVISION_DIV1;
  htim9.Init.AutoReloadPreload = TIM_AUTORELOAD_PRELOAD_DISABLE;
  if (HAL_TIM_PWM_Init(&htim9) != HAL_OK)
  {
    Error_Handler();
  }
  if (HAL_TIM_OnePulse_Init(&htim9, TIM_OPMODE_SINGLE) != HAL_OK)
  {
    Error_Handler();
  }
  sConfigOC.OCMode = TIM_OCMODE_PWM1;
  sConfigOC.Pulse = 0;
  sConfigOC.OCPolarity = TIM_OCPOLARITY_HIGH;
  sConfigOC.OCFastMode = TIM_OCFAST_DISABLE;
  if (HAL_TIM_PWM_ConfigChannel(&htim9, &sConfigOC, TIM_CHANNEL_1) != HAL_OK)
  {
    Error_Handler();
  }
  if (HAL_TIM_PWM_ConfigChannel(&htim9, &sConfigOC, TIM_CHANNEL_2) != HAL_OK)
  {
    Error_Handler();
  }
  HAL_TIM_MspPostInit(&htim9);

}

static void MX_TIM11_Init(void)
{

  TIM_OC_InitTypeDef sConfigOC = {0};

  htim11.Instance = TIM11;
  htim11.Init.Prescaler = 840-1;
  htim11.Init.CounterMode = TIM_COUNTERMODE_UP;
  htim11.Init.Period = 999;
  htim11.Init.ClockDivision = TIM_CLOCKDIVISION_DIV1;
  htim11.Init.AutoReloadPreload = TIM_AUTORELOAD_PRELOAD_DISABLE;
  if (HAL_TIM_Base_Init(&htim11) != HAL_OK)
  {
    Error_Handler();
  }
  if (HAL_TIM_PWM_Init(&htim11) != HAL_OK)
  {
    Error_Handler();
  }
  if (HAL_TIM_OnePulse_Init(&htim11, TIM_OPMODE_SINGLE) != HAL_OK)
  {
    Error_Handler();
  }
  sConfigOC.OCMode = TIM_OCMODE_PWM2;
  sConfigOC.Pulse = 0;
  sConfigOC.OCPolarity = TIM_OCPOLARITY_HIGH;
  sConfigOC.OCFastMode = TIM_OCFAST_DISABLE;
  if (HAL_TIM_PWM_ConfigChannel(&htim11, &sConfigOC, TIM_CHANNEL_1) != HAL_OK)
  {
    Error_Handler();
  }
  HAL_TIM_MspPostInit(&htim11);

}

static void MX_TIM13_Init(void)
{

  TIM_OC_InitTypeDef sConfigOC = {0};

  htim13.Instance = TIM13;
  htim13.Init.Prescaler = 840-1;
  htim13.Init.CounterMode = TIM_COUNTERMODE_UP;
  htim13.Init.Period = 999;
  htim13.Init.ClockDivision = TIM_CLOCKDIVISION_DIV1;
  htim13.Init.AutoReloadPreload = TIM_AUTORELOAD_PRELOAD_DISABLE;
  if (HAL_TIM_Base_Init(&htim13) != HAL_OK)
  {
    Error_Handler();
  }
  if (HAL_TIM_PWM_Init(&htim13) != HAL_OK)
  {
    Error_Handler();
  }
  if (HAL_TIM_OnePulse_Init(&htim13, TIM_OPMODE_SINGLE) != HAL_OK)
  {
    Error_Handler();
  }
  sConfigOC.OCMode = TIM_OCMODE_PWM2;
  sConfigOC.Pulse = 0;
  sConfigOC.OCPolarity = TIM_OCPOLARITY_HIGH;
  sConfigOC.OCFastMode = TIM_OCFAST_DISABLE;
  if (HAL_TIM_PWM_ConfigChannel(&htim13, &sConfigOC, TIM_CHANNEL_1) != HAL_OK)
  {
    Error_Handler();
  }
  HAL_TIM_MspPostInit(&htim13);

}

static void MX_TIM14_Init(void)
{

  TIM_OC_InitTypeDef sConfigOC = {0};

  htim14.Instance = TIM14;
  htim14.Init.Prescaler = 840-1;
  htim14.Init.CounterMode = TIM_COUNTERMODE_UP;
  htim14.Init.Period = 999;
  htim14.Init.ClockDivision = TIM_CLOCKDIVISION_DIV1;
  htim14.Init.AutoReloadPreload = TIM_AUTORELOAD_PRELOAD_DISABLE;
  if (HAL_TIM_Base_Init(&htim14) != HAL_OK)
  {
    Error_Handler();
  }
  if (HAL_TIM_PWM_Init(&htim14) != HAL_OK)
  {
    Error_Handler();
  }
  if (HAL_TIM_OnePulse_Init(&htim14, TIM_OPMODE_SINGLE) != HAL_OK)
  {
    Error_Handler();
  }
  sConfigOC.OCMode = TIM_OCMODE_PWM2;
  sConfigOC.Pulse = 0;
  sConfigOC.OCPolarity = TIM_OCPOLARITY_HIGH;
  sConfigOC.OCFastMode = TIM_OCFAST_DISABLE;
  if (HAL_TIM_PWM_ConfigChannel(&htim14, &sConfigOC, TIM_CHANNEL_1) != HAL_OK)
  {
    Error_Handler();
  }
  HAL_TIM_MspPostInit(&htim14);

}

static void MX_UART4_Init(void)
{

  huart4.Instance = UART4;
  huart4.Init.BaudRate = 57600;
  huart4.Init.WordLength = UART_WORDLENGTH_8B;
  huart4.Init.StopBits = UART_STOPBITS_2;
  huart4.Init.Parity = UART_PARITY_EVEN;
  huart4.Init.Mode = UART_MODE_TX_RX;
  huart4.Init.HwFlowCtl = UART_HWCONTROL_NONE;
  huart4.Init.OverSampling = UART_OVERSAMPLING_16;
  if (HAL_UART_Init(&huart4) != HAL_OK)
  {
    Error_Handler();
  }

}

static void MX_DMA_Init(void)
{

  /* DMA controller clock enable */
  __HAL_RCC_DMA2_CLK_ENABLE();
  __HAL_RCC_DMA1_CLK_ENABLE();

  /* DMA interrupt init */
  /* DMA1_Stream2_IRQn interrupt configuration */
  HAL_NVIC_SetPriority(DMA1_Stream2_IRQn, 5, 0);
  HAL_NVIC_EnableIRQ(DMA1_Stream2_IRQn);
  /* DMA1_Stream4_IRQn interrupt configuration */
  HAL_NVIC_SetPriority(DMA1_Stream4_IRQn, 5, 0);
  HAL_NVIC_EnableIRQ(DMA1_Stream4_IRQn);
  /* DMA2_Stream0_IRQn interrupt configuration */
  HAL_NVIC_SetPriority(DMA2_Stream0_IRQn, 5, 0);
  HAL_NVIC_EnableIRQ(DMA2_Stream0_IRQn);

}

static void MX_GPIO_Init(void)
{
  GPIO_InitTypeDef GPIO_InitStruct = {0};

  /* GPIO Ports Clock Enable */
  __HAL_RCC_GPIOE_CLK_ENABLE();
  __HAL_RCC_GPIOC_CLK_ENABLE();
  __HAL_RCC_GPIOF_CLK_ENABLE();
  __HAL_RCC_GPIOH_CLK_ENABLE();
  __HAL_RCC_GPIOA_CLK_ENABLE();
  __HAL_RCC_GPIOB_CLK_ENABLE();
  __HAL_RCC_GPIOG_CLK_ENABLE();
  __HAL_RCC_GPIOD_CLK_ENABLE();

  /*Configure GPIO pin Output Level */
  HAL_GPIO_WritePin(GPIOC, DO_305_Feed_y_Pin|Q7_Pin|Q8_Pin|DO_308_Clamp_x_Pin
                          |DO_306_Feed_z_Pin, GPIO_PIN_SET);

  /*Configure GPIO pin Output Level */
  HAL_GPIO_WritePin(GPIOC, SPI_CS_Pin|INT_Pin|RST_Pin, GPIO_PIN_RESET);

  /*Configure GPIO pin Output Level */
  HAL_GPIO_WritePin(GPIOG, DO_304_Feed_x_Pin|DO_310_Clamp_y_Pin|DO_312_Clamp_z_Pin|led_oil_Pin
                          |led_Temper_Pin|DO_63_K7_Pin|DO_51_K6_Pin|res_do24v1_Pin, GPIO_PIN_SET);

  /*Configure GPIO pin Output Level */
  HAL_GPIO_WritePin(GPIOB, Q2_Pin|Q3_Pin|Q4_Pin|Q5_Pin
                          |Q6_Pin|res_do24v2_Pin|led_reserve1_m_Pin|led_X_lock_m_Pin
                          |led_Z_lock_m_Pin|led_Y_lock_m_Pin|led_reserve3_m_Pin|led_2t_m_Pin, GPIO_PIN_SET);

  /*Configure GPIO pin Output Level */
  HAL_GPIO_WritePin(RE_DE_GPIO_Port, RE_DE_Pin, GPIO_PIN_RESET);

  /*Configure GPIO pin Output Level */
  HAL_GPIO_WritePin(GPIOE, led_manual_Pin|led_error_m_Pin, GPIO_PIN_SET);

  /*Configure GPIO pins : PE2 PE3 PE7 PE8
                           PE10 PE12 */
  GPIO_InitStruct.Pin = GPIO_PIN_2|GPIO_PIN_3|GPIO_PIN_7|GPIO_PIN_8
                          |GPIO_PIN_10|GPIO_PIN_12;
  GPIO_InitStruct.Mode = GPIO_MODE_ANALOG;
  GPIO_InitStruct.Pull = GPIO_NOPULL;
  HAL_GPIO_Init(GPIOE, &GPIO_InitStruct);

  /*Configure GPIO pin : EXTI_A_Pin */
  GPIO_InitStruct.Pin = EXTI_A_Pin;
  GPIO_InitStruct.Mode = GPIO_MODE_IT_RISING;
  GPIO_InitStruct.Pull = GPIO_NOPULL;
  HAL_GPIO_Init(EXTI_A_GPIO_Port, &GPIO_InitStruct);

  /*Configure GPIO pins : DO_305_Feed_y_Pin Q7_Pin Q8_Pin DO_308_Clamp_x_Pin
                           DO_306_Feed_z_Pin */
  GPIO_InitStruct.Pin = DO_305_Feed_y_Pin|Q7_Pin|Q8_Pin|DO_308_Clamp_x_Pin
                          |DO_306_Feed_z_Pin;
  GPIO_InitStruct.Mode = GPIO_MODE_OUTPUT_OD;
  GPIO_InitStruct.Pull = GPIO_NOPULL;
  GPIO_InitStruct.Speed = GPIO_SPEED_FREQ_LOW;
  HAL_GPIO_Init(GPIOC, &GPIO_InitStruct);

  /*Configure GPIO pins : PC14 PC15 */
  GPIO_InitStruct.Pin = GPIO_PIN_14|GPIO_PIN_15;
  GPIO_InitStruct.Mode = GPIO_MODE_ANALOG;
  GPIO_InitStruct.Pull = GPIO_NOPULL;
  HAL_GPIO_Init(GPIOC, &GPIO_InitStruct);

  /*Configure GPIO pins : S2rocking_Pin S28Z_endswitch1_Pin S25Z_endswitch2_Pin S27Y_endswitch1_Pin
                           DI_82_S13_m_Pin DI_34_S8_m_Pin DI_34_S7_m_Pin S6_m1_on_m_Pin
                           ReserveDI2_m_Pin DI_26_S4_m_Pin DI_87_S15_m_Pin */
  GPIO_InitStruct.Pin = S2rocking_Pin|S28Z_endswitch1_Pin|S25Z_endswitch2_Pin|S27Y_endswitch1_Pin
                          |DI_82_S13_m_Pin|DI_34_S8_m_Pin|DI_34_S7_m_Pin|S6_m1_on_m_Pin
                          |ReserveDI2_m_Pin|DI_26_S4_m_Pin|DI_87_S15_m_Pin;
  GPIO_InitStruct.Mode = GPIO_MODE_INPUT;
  GPIO_InitStruct.Pull = GPIO_NOPULL;
  HAL_GPIO_Init(GPIOF, &GPIO_InitStruct);

  /*Configure GPIO pins : EXTI_B_Pin EXTI_C_Pin */
  GPIO_InitStruct.Pin = EXTI_B_Pin|EXTI_C_Pin;
  GPIO_InitStruct.Mode = GPIO_MODE_IT_RISING_FALLING;
  GPIO_InitStruct.Pull = GPIO_NOPULL;
  HAL_GPIO_Init(GPIOF, &GPIO_InitStruct);

  /*Configure GPIO pins : DI_277_S31_m_Pin DI_276_S30_m_Pin DI_275_S29_m_Pin DI_260_S22_m_Pin
                           DI_203_S35_m_Pin DI_280_S34_m_Pin DI_279_S33_m_Pin DI_278_S32_m_Pin */
  GPIO_InitStruct.Pin = DI_277_S31_m_Pin|DI_276_S30_m_Pin|DI_275_S29_m_Pin|DI_260_S22_m_Pin
                          |DI_203_S35_m_Pin|DI_280_S34_m_Pin|DI_279_S33_m_Pin|DI_278_S32_m_Pin;
  GPIO_InitStruct.Mode = GPIO_MODE_INPUT;
  GPIO_InitStruct.Pull = GPIO_NOPULL;
  HAL_GPIO_Init(GPIOA, &GPIO_InitStruct);

  /*Configure GPIO pins : SPI_CS_Pin INT_Pin RST_Pin */
  GPIO_InitStruct.Pin = SPI_CS_Pin|INT_Pin|RST_Pin;
  GPIO_InitStruct.Mode = GPIO_MODE_OUTPUT_PP;
  GPIO_InitStruct.Pull = GPIO_NOPULL;
  GPIO_InitStruct.Speed = GPIO_SPEED_FREQ_LOW;
  HAL_GPIO_Init(GPIOC, &GPIO_InitStruct);

  /*Configure GPIO pins : PB0 PB1 PB2 */
  GPIO_InitStruct.Pin = GPIO_PIN_0|GPIO_PIN_1|GPIO_PIN_2;
  GPIO_InitStruct.Mode = GPIO_MODE_ANALOG;
  GPIO_InitStruct.Pull = GPIO_NOPULL;
  HAL_GPIO_Init(GPIOB, &GPIO_InitStruct);

  /*Configure GPIO pins : DO_304_Feed_x_Pin DO_310_Clamp_y_Pin DO_312_Clamp_z_Pin led_oil_Pin
                           led_Temper_Pin DO_63_K7_Pin DO_51_K6_Pin res_do24v1_Pin */
  GPIO_InitStruct.Pin = DO_304_Feed_x_Pin|DO_310_Clamp_y_Pin|DO_312_Clamp_z_Pin|led_oil_Pin
                          |led_Temper_Pin|DO_63_K7_Pin|DO_51_K6_Pin|res_do24v1_Pin;
  GPIO_InitStruct.Mode = GPIO_MODE_OUTPUT_OD;
  GPIO_InitStruct.Pull = GPIO_NOPULL;
  GPIO_InitStruct.Speed = GPIO_SPEED_FREQ_LOW;
  HAL_GPIO_Init(GPIOG, &GPIO_InitStruct);

  /*Configure GPIO pins : PG1 PG2 PG3 PG4
                           PG5 PG6 PG7 */
  GPIO_InitStruct.Pin = GPIO_PIN_1|GPIO_PIN_2|GPIO_PIN_3|GPIO_PIN_4
                          |GPIO_PIN_5|GPIO_PIN_6|GPIO_PIN_7;
  GPIO_InitStruct.Mode = GPIO_MODE_ANALOG;
  GPIO_InitStruct.Pull = GPIO_NOPULL;
  HAL_GPIO_Init(GPIOG, &GPIO_InitStruct);

  /*Configure GPIO pins : tacho_dir_right_Pin tacho_dir_left_Pin DI_63_S9_m_Pin */
  GPIO_InitStruct.Pin = tacho_dir_right_Pin|tacho_dir_left_Pin|DI_63_S9_m_Pin;
  GPIO_InitStruct.Mode = GPIO_MODE_INPUT;
  GPIO_InitStruct.Pull = GPIO_NOPULL;
  HAL_GPIO_Init(GPIOE, &GPIO_InitStruct);

  /*Configure GPIO pins : Q2_Pin Q3_Pin Q4_Pin Q5_Pin
                           Q6_Pin res_do24v2_Pin led_reserve1_m_Pin led_X_lock_m_Pin
                           led_Z_lock_m_Pin led_Y_lock_m_Pin led_reserve3_m_Pin led_2t_m_Pin */
  GPIO_InitStruct.Pin = Q2_Pin|Q3_Pin|Q4_Pin|Q5_Pin
                          |Q6_Pin|res_do24v2_Pin|led_reserve1_m_Pin|led_X_lock_m_Pin
                          |led_Z_lock_m_Pin|led_Y_lock_m_Pin|led_reserve3_m_Pin|led_2t_m_Pin;
  GPIO_InitStruct.Mode = GPIO_MODE_OUTPUT_OD;
  GPIO_InitStruct.Pull = GPIO_NOPULL;
  GPIO_InitStruct.Speed = GPIO_SPEED_FREQ_LOW;
  HAL_GPIO_Init(GPIOB, &GPIO_InitStruct);

  /*Configure GPIO pins : DI_252_m_Pin DI_246_m_Pin DI_253_m_Pin DI_29_S5_m_Pin
                           DI_92_S20_m_Pin DI_91_S19_m_Pin DI_90_S18_m_Pin DI_88_S16_m_Pin
                           DI_89_S17_m_Pin ESD_m_Pin F1_DI_m_Pin F2_DI_m_Pin
                           F3_DI_m_Pin S6Gearbox_Pin S11Gripe_Pin S12ungrip_Pin */
  GPIO_InitStruct.Pin = DI_252_m_Pin|DI_246_m_Pin|DI_253_m_Pin|DI_29_S5_m_Pin
                          |DI_92_S20_m_Pin|DI_91_S19_m_Pin|DI_90_S18_m_Pin|DI_88_S16_m_Pin
                          |DI_89_S17_m_Pin|ESD_m_Pin|F1_DI_m_Pin|F2_DI_m_Pin
                          |F3_DI_m_Pin|S6Gearbox_Pin|S11Gripe_Pin|S12ungrip_Pin;
  GPIO_InitStruct.Mode = GPIO_MODE_INPUT;
  GPIO_InitStruct.Pull = GPIO_NOPULL;
  HAL_GPIO_Init(GPIOD, &GPIO_InitStruct);

  /*Configure GPIO pin : RE_DE_Pin */
  GPIO_InitStruct.Pin = RE_DE_Pin;
  GPIO_InitStruct.Mode = GPIO_MODE_OUTPUT_PP;
  GPIO_InitStruct.Pull = GPIO_NOPULL;
  GPIO_InitStruct.Speed = GPIO_SPEED_FREQ_LOW;
  HAL_GPIO_Init(RE_DE_GPIO_Port, &GPIO_InitStruct);

  /*Configure GPIO pin : PA15 */
  GPIO_InitStruct.Pin = GPIO_PIN_15;
  GPIO_InitStruct.Mode = GPIO_MODE_ANALOG;
  GPIO_InitStruct.Pull = GPIO_NOPULL;
  HAL_GPIO_Init(GPIOA, &GPIO_InitStruct);

  /*Configure GPIO pins : led_manual_Pin led_error_m_Pin */
  GPIO_InitStruct.Pin = led_manual_Pin|led_error_m_Pin;
  GPIO_InitStruct.Mode = GPIO_MODE_OUTPUT_OD;
  GPIO_InitStruct.Pull = GPIO_NOPULL;
  GPIO_InitStruct.Speed = GPIO_SPEED_FREQ_LOW;
  HAL_GPIO_Init(GPIOE, &GPIO_InitStruct);

}

/* USER CODE BEGIN 4 */
//---------------------------exti--------------------//

void EXTI4_IRQHandler(void)
{

    HAL_GPIO_EXTI_IRQHandler(EXTI_A_Pin);
    if (HAL_GPIO_ReadPin(EXTI_A_GPIO_Port,EXTI_A_Pin)==GPIO_PIN_SET)   //polyarity hight
    {
      if(polyarity==0){
        HAL_TIM_PWM_Start(&htim1, TIM_CHANNEL_2);
      }
    __HAL_TIM_SET_COUNTER(&htim3,0);
    }else{
      if(polyarity==1){
        HAL_TIM_PWM_Start(&htim1, TIM_CHANNEL_1);
      }
    }
    //-----M1---//
    TIM11->CCR1=PWM_M1;
    HAL_TIM_PWM_Start(&htim11, TIM_CHANNEL_1);
}
void EXTI2_IRQHandler(void)
{

    HAL_GPIO_EXTI_IRQHandler(EXTI_B_Pin);
    if (HAL_GPIO_ReadPin(EXTI_B_GPIO_Port,EXTI_B_Pin)==GPIO_PIN_SET)
    {
      //polyarity hight
    Time_b=TIM3->CNT;
      if(polyarity==0){
        HAL_TIM_PWM_Start(&htim9, TIM_CHANNEL_2);
      }
    }else{
       if(polyarity==1){
        HAL_TIM_PWM_Start(&htim9, TIM_CHANNEL_1);
      }
    }
    //-----M1---//
    TIM13->CCR1=PWM_M1;
    HAL_TIM_PWM_Start(&htim13, TIM_CHANNEL_1);
}
void EXTI3_IRQHandler(void)
{
    HAL_GPIO_EXTI_IRQHandler(EXTI_C_Pin);
    if (HAL_GPIO_ReadPin(EXTI_C_GPIO_Port,EXTI_C_Pin)==GPIO_PIN_SET)
    {
      if(polyarity==0){
        HAL_TIM_PWM_Start(&htim8, TIM_CHANNEL_2);
      }
    Time_c=TIM3->CNT;
    }else{
      if(polyarity==1){
        HAL_TIM_PWM_Start(&htim8, TIM_CHANNEL_1);
      }
    }
    //-----M1---//
    TIM14->CCR1=PWM_M1;
    HAL_TIM_PWM_Start(&htim14, TIM_CHANNEL_1);
}

//====================================================//
/* USER CODE END 4 */

void StartMainTask(void *argument)
{
  /* USER CODE BEGIN 5 */
  HAL_GPIO_WritePin(DO_51_K6_GPIO_Port,DO_51_K6_Pin,GPIO_PIN_SET);
  HAL_GPIO_WritePin(DO_63_K7_GPIO_Port,DO_63_K7_Pin,GPIO_PIN_SET);
  HAL_ADC_Stop(&hadc1);
  HAL_ADC_Stop_DMA(&hadc1);
  HAL_ADC_Start_DMA(&hadc1,(uint32_t*)&dma,4);
  NVIC_EnableIRQ(EXTI2_IRQn);
  NVIC_EnableIRQ(EXTI3_IRQn);
  NVIC_EnableIRQ(EXTI4_IRQn);
  NVIC_EnableIRQ(TIM2_IRQn);
  HAL_TIM_IC_Start_IT(&htim2,TIM_CHANNEL_1);
  osDelay(50);
  static uint8_t oil_pump_state=0, limit_switches=0; // feed_motion 1- x left, 2-x right, 3-y left, 4-y right, 5-z up, 6-z down same for limit swiches but coded in bits

  uint16_t feed_sp_buf[3]={0}, I_M4_buf[3]={0},feed_sp_temp, I_M4_temp;
  struct button_without_fix {
     GPIO_PinState pos_current;
     GPIO_PinState pos_previous;
  };
  struct button_without_fix X_left= {GPIO_PIN_RESET,GPIO_PIN_RESET}, X_right= {GPIO_PIN_RESET,GPIO_PIN_RESET}, Y_left= {GPIO_PIN_RESET,GPIO_PIN_RESET},
  Y_right= {GPIO_PIN_RESET,GPIO_PIN_RESET}, Z_up= {GPIO_PIN_RESET,GPIO_PIN_RESET}, Z_down={GPIO_PIN_RESET,GPIO_PIN_RESET}, lock_All={GPIO_PIN_RESET,GPIO_PIN_RESET},
  Unlock_X={GPIO_PIN_RESET,GPIO_PIN_RESET}, Unlock_Y={GPIO_PIN_RESET,GPIO_PIN_RESET}, Unlock_Z={GPIO_PIN_RESET,GPIO_PIN_RESET}, Feed_Stop={GPIO_PIN_RESET,GPIO_PIN_RESET},
  M1_on={GPIO_PIN_RESET,GPIO_PIN_RESET}, M1_off={GPIO_PIN_RESET,GPIO_PIN_RESET}, Oil_pump={GPIO_PIN_RESET,GPIO_PIN_RESET}, auto_man={GPIO_PIN_RESET,GPIO_PIN_RESET}, Rocking_btn={GPIO_PIN_RESET,GPIO_PIN_RESET},
  Deblock_btn={GPIO_PIN_RESET,GPIO_PIN_RESET};
  uint8_t i;
  /* Infinite loop */
  for(;;)
  {
    HAL_IWDG_Refresh(&hiwdg);

    // phase error
    if (Time_b>Time_c){
      error_my=1;
    }
    // ESD error
    if (HAL_GPIO_ReadPin(ESD_m_GPIO_Port,ESD_m_Pin)==GPIO_PIN_SET)
    {
      error_my=2;
    }
    // Temperature error F1
    if (HAL_GPIO_ReadPin(F1_DI_m_GPIO_Port,F1_DI_m_Pin)==GPIO_PIN_SET)
    {
      error_my=3;
      HAL_GPIO_WritePin(led_Temper_GPIO_Port,led_Temper_Pin, GPIO_PIN_RESET);
    }
    // Temperature error F2
    if (HAL_GPIO_ReadPin(F2_DI_m_GPIO_Port,F2_DI_m_Pin)==GPIO_PIN_SET)
    {
      error_my=4;
      HAL_GPIO_WritePin(led_Temper_GPIO_Port,led_Temper_Pin, GPIO_PIN_RESET);
    }
    // Temperature error F3
    if (HAL_GPIO_ReadPin(F3_DI_m_GPIO_Port,F3_DI_m_Pin)==GPIO_PIN_SET)
    {
      error_my=5;
      HAL_GPIO_WritePin(led_Temper_GPIO_Port,led_Temper_Pin, GPIO_PIN_RESET);
    }

     // oil pump on
    Oil_pump.pos_previous=Oil_pump.pos_current;
    Oil_pump.pos_current=HAL_GPIO_ReadPin(DI_26_S4_m_GPIO_Port,DI_26_S4_m_Pin);
    if ((Oil_pump.pos_previous==GPIO_PIN_SET)&(Oil_pump.pos_current==GPIO_PIN_RESET))
    {
      oil_pump_state=~oil_pump_state;
    }

    //auto man btn
    auto_man.pos_previous=auto_man.pos_current;
    auto_man.pos_current=HAL_GPIO_ReadPin(DI_203_S35_m_GPIO_Port,DI_203_S35_m_Pin);
    if ((auto_man.pos_previous==GPIO_PIN_SET)&(auto_man.pos_current==GPIO_PIN_RESET))
    {
      HAL_GPIO_TogglePin(led_manual_GPIO_Port,led_manual_Pin);
    }

      // lock xyz
    lock_All.pos_previous=lock_All.pos_current;
    lock_All.pos_current=HAL_GPIO_ReadPin(DI_87_S15_m_GPIO_Port,DI_87_S15_m_Pin);
    if ((lock_All.pos_previous==GPIO_PIN_SET) && (lock_All.pos_current==GPIO_PIN_RESET))
    {
      if ((feed_motion!=1)||(feed_motion!=2))
      {
        HAL_GPIO_WritePin(DO_308_Clamp_x_GPIO_Port,DO_308_Clamp_x_Pin,GPIO_PIN_RESET);
        HAL_GPIO_WritePin(led_X_lock_m_GPIO_Port,led_X_lock_m_Pin,GPIO_PIN_RESET);
      }
      if ((feed_motion!=3)||(feed_motion!=4))
      {
        HAL_GPIO_WritePin(DO_310_Clamp_y_GPIO_Port,DO_310_Clamp_y_Pin,GPIO_PIN_RESET);
        HAL_GPIO_WritePin(led_Y_lock_m_GPIO_Port,led_Y_lock_m_Pin,GPIO_PIN_RESET);
      }
      if ((feed_motion!=5)||(feed_motion!=6))
      {
        HAL_GPIO_WritePin(DO_312_Clamp_z_GPIO_Port,DO_312_Clamp_z_Pin,GPIO_PIN_RESET);
        HAL_GPIO_WritePin(led_Z_lock_m_GPIO_Port,led_Z_lock_m_Pin,GPIO_PIN_RESET);  //reset mens on
      }
    }
    //unclamp X
    Unlock_X.pos_previous=Unlock_X.pos_current;
    Unlock_X.pos_current=HAL_GPIO_ReadPin(DI_88_S16_m_GPIO_Port,DI_88_S16_m_Pin);
    if ((Unlock_X.pos_previous==GPIO_PIN_SET)&&(Unlock_X.pos_current==GPIO_PIN_RESET))
    {
      HAL_GPIO_WritePin(led_X_lock_m_GPIO_Port,led_X_lock_m_Pin,GPIO_PIN_SET);
      HAL_GPIO_WritePin(DO_308_Clamp_x_GPIO_Port,DO_308_Clamp_x_Pin,GPIO_PIN_SET);
    }
    //unclamp Y
    Unlock_Y.pos_previous=Unlock_Y.pos_current;
    Unlock_Y.pos_current=HAL_GPIO_ReadPin(DI_89_S17_m_GPIO_Port,DI_89_S17_m_Pin);
    if ((Unlock_Y.pos_previous==GPIO_PIN_SET)&&(Unlock_Y.pos_current==GPIO_PIN_RESET))
    {
      HAL_GPIO_WritePin(led_Y_lock_m_GPIO_Port,led_Y_lock_m_Pin,GPIO_PIN_SET);
      HAL_GPIO_WritePin(DO_310_Clamp_y_GPIO_Port,DO_310_Clamp_y_Pin,GPIO_PIN_SET);
    }
    //unclamp Z
    Unlock_Z.pos_previous=Unlock_Z.pos_current;
    Unlock_Z.pos_current=HAL_GPIO_ReadPin(DI_90_S18_m_GPIO_Port,DI_90_S18_m_Pin);
    if ((Unlock_Z.pos_previous==GPIO_PIN_SET)&&(Unlock_Z.pos_current==GPIO_PIN_RESET))
    {
      HAL_GPIO_WritePin(led_Z_lock_m_GPIO_Port,led_Z_lock_m_Pin,GPIO_PIN_SET);
      HAL_GPIO_WritePin(DO_312_Clamp_z_GPIO_Port,DO_312_Clamp_z_Pin,GPIO_PIN_SET);
    }

    //motion defenition 2 t 4 t  man/auto end swich
    X_left.pos_previous=X_left.pos_current;
    X_left.pos_current=HAL_GPIO_ReadPin(DI_276_S30_m_GPIO_Port,DI_276_S30_m_Pin);

    X_right.pos_previous=X_right.pos_current;
    X_right.pos_current=HAL_GPIO_ReadPin(DI_275_S29_m_GPIO_Port,DI_275_S29_m_Pin);

    Y_left.pos_previous=Y_left.pos_current;
    Y_left.pos_current=HAL_GPIO_ReadPin(DI_278_S32_m_GPIO_Port,DI_278_S32_m_Pin);

    Y_right.pos_previous=Y_right.pos_current;
    Y_right.pos_current=HAL_GPIO_ReadPin(DI_277_S31_m_GPIO_Port,DI_277_S31_m_Pin);

    Z_up.pos_previous=Z_up.pos_current;
    Z_up.pos_current=HAL_GPIO_ReadPin(DI_280_S34_m_GPIO_Port,DI_280_S34_m_Pin);

    Z_down.pos_previous=Z_down.pos_current;
    Z_down.pos_current=HAL_GPIO_ReadPin(DI_279_S33_m_GPIO_Port,DI_279_S33_m_Pin);

    limit_switches= HAL_GPIO_ReadPin(DI_246_m_GPIO_Port,DI_246_m_Pin)+HAL_GPIO_ReadPin(DI_253_m_GPIO_Port,DI_253_m_Pin)*2+HAL_GPIO_ReadPin(DI_252_m_GPIO_Port,DI_252_m_Pin)*4+HAL_GPIO_ReadPin(S27Y_endswitch1_GPIO_Port,S27Y_endswitch1_Pin)*8+HAL_GPIO_ReadPin(S25Z_endswitch2_GPIO_Port,S25Z_endswitch2_Pin)*16+HAL_GPIO_ReadPin(S28Z_endswitch1_GPIO_Port,S28Z_endswitch1_Pin)*32;

    if ((HAL_GPIO_ReadPin(DI_82_S13_m_GPIO_Port,DI_82_S13_m_Pin)==GPIO_PIN_SET)&&(feed_motion==0)) //2t 4t feed control mode
    {
      if ((X_left.pos_previous==GPIO_PIN_SET)&&(X_left.pos_current==GPIO_PIN_RESET))
      {
        feed_motion=1;
        polyarity=1;
      }
      if ((X_right.pos_previous==GPIO_PIN_SET)&&(X_right.pos_current==GPIO_PIN_RESET))
      {
        feed_motion=2;
        polyarity=0;
      }
      if ((Y_left.pos_previous==GPIO_PIN_SET)&&(Y_left.pos_current==GPIO_PIN_RESET))
      {
        feed_motion=3;
        polyarity=1;
      }
      if ((Y_right.pos_previous==GPIO_PIN_SET)&&(Y_right.pos_current==GPIO_PIN_RESET))
      {
        feed_motion=4;
        polyarity=0;
      }
      if ((Z_up.pos_previous==GPIO_PIN_SET)&&(Z_up.pos_current==GPIO_PIN_RESET))
      {
        feed_motion=5;
        polyarity=1;
      }
      if ((Z_down.pos_previous==GPIO_PIN_SET)&&(Z_down.pos_current==GPIO_PIN_RESET))
      {
        feed_motion=6;
        polyarity=0;
      }
    } else if (feed_motion==0) {
      if (X_left.pos_current==GPIO_PIN_SET)
      {
        feed_motion=1;
        polyarity=1;
      }
      if (X_right.pos_current==GPIO_PIN_SET)
      {
        feed_motion=2;
        polyarity=0;
      }
      if (Y_left.pos_current==GPIO_PIN_SET)
      {
        feed_motion=3;
        polyarity=1;
      }
      if (Y_right.pos_current==GPIO_PIN_SET)
      {
        feed_motion=4;
        polyarity=0;
      }
      if (Z_up.pos_current==GPIO_PIN_SET)
      {
        feed_motion=5;
        polyarity=1;
      }
      if (Z_down.pos_current==GPIO_PIN_SET)
      {
        feed_motion=6;
        polyarity=0;
      }
      if (!(X_left.pos_current|X_right.pos_current|Y_left.pos_current|Y_right.pos_current|Z_up.pos_current|Z_down.pos_current))
      {
        feed_motion=0;
      }
    }

    Feed_Stop.pos_previous=Feed_Stop.pos_current;
    Feed_Stop.pos_current=HAL_GPIO_ReadPin(DI_260_S22_m_GPIO_Port,DI_260_S22_m_Pin);
    if (((Feed_Stop.pos_previous==GPIO_PIN_SET)&&(Feed_Stop.pos_current==GPIO_PIN_RESET))||(error_my!=0))
    {
      feed_motion=0;
    }

    switch (feed_motion) //check endswiches
    {
    case 0:
      HAL_GPIO_WritePin(DO_304_Feed_x_GPIO_Port,DO_304_Feed_x_Pin,GPIO_PIN_SET);  //cluch engadement
      HAL_GPIO_WritePin(DO_306_Feed_z_GPIO_Port,DO_306_Feed_z_Pin,GPIO_PIN_SET);  //cluch engadement
      HAL_GPIO_WritePin(DO_305_Feed_y_GPIO_Port,DO_305_Feed_y_Pin,GPIO_PIN_SET);  //cluch engadement

      break;
    case 1:
      if (limit_switches&1){
        feed_motion=0;
      } else{
        HAL_GPIO_WritePin(led_X_lock_m_GPIO_Port,led_X_lock_m_Pin,GPIO_PIN_SET);
        HAL_GPIO_WritePin(DO_308_Clamp_x_GPIO_Port,DO_308_Clamp_x_Pin,GPIO_PIN_SET);
        HAL_GPIO_WritePin(DO_304_Feed_x_GPIO_Port,DO_304_Feed_x_Pin,GPIO_PIN_RESET);  //cluch engadement
        HAL_GPIO_WritePin(DO_306_Feed_z_GPIO_Port,DO_306_Feed_z_Pin,GPIO_PIN_SET);  //cluch engadement
        HAL_GPIO_WritePin(DO_305_Feed_y_GPIO_Port,DO_305_Feed_y_Pin,GPIO_PIN_SET);  //cluch engadement
      }
      break;
    case 2:
      if (limit_switches&2){
        feed_motion=0;
      } else{
        HAL_GPIO_WritePin(led_X_lock_m_GPIO_Port,led_X_lock_m_Pin,GPIO_PIN_SET);
        HAL_GPIO_WritePin(DO_308_Clamp_x_GPIO_Port,DO_308_Clamp_x_Pin,GPIO_PIN_SET);
        HAL_GPIO_WritePin(DO_304_Feed_x_GPIO_Port,DO_304_Feed_x_Pin,GPIO_PIN_RESET);  //cluch engadement
        HAL_GPIO_WritePin(DO_306_Feed_z_GPIO_Port,DO_306_Feed_z_Pin,GPIO_PIN_SET);  //cluch engadement
        HAL_GPIO_WritePin(DO_305_Feed_y_GPIO_Port,DO_305_Feed_y_Pin,GPIO_PIN_SET);  //cluch engadement
      }
      break;
    case 3:
      if (limit_switches&4){
        feed_motion=0;
      } else {
        HAL_GPIO_WritePin(led_Y_lock_m_GPIO_Port,led_Y_lock_m_Pin,GPIO_PIN_SET);
        HAL_GPIO_WritePin(DO_310_Clamp_y_GPIO_Port,DO_310_Clamp_y_Pin,GPIO_PIN_SET);
        HAL_GPIO_WritePin(DO_305_Feed_y_GPIO_Port,DO_305_Feed_y_Pin,GPIO_PIN_RESET);  //cluch engadement
        HAL_GPIO_WritePin(DO_304_Feed_x_GPIO_Port,DO_304_Feed_x_Pin,GPIO_PIN_SET);  //cluch engadement
        HAL_GPIO_WritePin(DO_306_Feed_z_GPIO_Port,DO_306_Feed_z_Pin,GPIO_PIN_SET);  //cluch engadement
      }
      break;
    case 4:
      if (limit_switches&8){
        feed_motion=0;
      } else {
        HAL_GPIO_WritePin(led_Y_lock_m_GPIO_Port,led_Y_lock_m_Pin,GPIO_PIN_SET);
        HAL_GPIO_WritePin(DO_310_Clamp_y_GPIO_Port,DO_310_Clamp_y_Pin,GPIO_PIN_SET);
        HAL_GPIO_WritePin(DO_305_Feed_y_GPIO_Port,DO_305_Feed_y_Pin,GPIO_PIN_RESET);  //cluch engadement
        HAL_GPIO_WritePin(DO_304_Feed_x_GPIO_Port,DO_304_Feed_x_Pin,GPIO_PIN_SET);  //cluch engadement
        HAL_GPIO_WritePin(DO_306_Feed_z_GPIO_Port,DO_306_Feed_z_Pin,GPIO_PIN_SET);  //cluch engadement
      }
      break;
    case 5:
      if (limit_switches&16){
        feed_motion=0;
      } else {
        HAL_GPIO_WritePin(led_Z_lock_m_GPIO_Port,led_Z_lock_m_Pin,GPIO_PIN_SET);
        HAL_GPIO_WritePin(DO_312_Clamp_z_GPIO_Port,DO_312_Clamp_z_Pin,GPIO_PIN_SET);
        HAL_GPIO_WritePin(DO_306_Feed_z_GPIO_Port,DO_306_Feed_z_Pin,GPIO_PIN_RESET); //cluch engadement
        HAL_GPIO_WritePin(DO_305_Feed_y_GPIO_Port,DO_305_Feed_y_Pin,GPIO_PIN_SET);  //cluch engadement
        HAL_GPIO_WritePin(DO_304_Feed_x_GPIO_Port,DO_304_Feed_x_Pin,GPIO_PIN_SET);  //cluch engadement
      }
      break;
    case 6:
      if (limit_switches&32){
        feed_motion=0;
      } else {
        HAL_GPIO_WritePin(led_Z_lock_m_GPIO_Port,led_Z_lock_m_Pin,GPIO_PIN_SET);
        HAL_GPIO_WritePin(DO_312_Clamp_z_GPIO_Port,DO_312_Clamp_z_Pin,GPIO_PIN_SET);
        HAL_GPIO_WritePin(DO_306_Feed_z_GPIO_Port,DO_306_Feed_z_Pin,GPIO_PIN_RESET);  //cluch engadement
        HAL_GPIO_WritePin(DO_305_Feed_y_GPIO_Port,DO_305_Feed_y_Pin,GPIO_PIN_SET);  //cluch engadement
        HAL_GPIO_WritePin(DO_304_Feed_x_GPIO_Port,DO_304_Feed_x_Pin,GPIO_PIN_SET);  //cluch engadement
      }
      break;
    }
    // feed speed I_M4

    for (i=0; i>1; i++){
      feed_sp_buf[i]=feed_sp_buf[i+1];
      I_M4_buf[i]=I_M4_buf[i+1];
    }
    feed_sp_buf[2]=dma[1]>4096?0:dma[1];
    feed_sp_temp=0;
    I_M4_buf[2]=dma[3]>4096?0:dma[3];
    I_M4_temp=0;
    for (i=0; i>2; i++){
      feed_sp_temp+=feed_sp_buf[i];
      I_M4_temp+=I_M4_buf[i];
    }
    I_M4=I_M4_temp/12; //0-1024
    if (HAL_GPIO_ReadPin(DI_91_S19_m_GPIO_Port,DI_91_S19_m_Pin)==GPIO_PIN_SET)
    {
      feed_speed_sp=feed_sp_temp/120;    //0-1000 /3-buf /4-1024/ 10- 100
      HAL_GPIO_WritePin(led_2t_m_GPIO_Port,led_2t_m_Pin,GPIO_PIN_RESET);
    } else{
      feed_speed_sp=feed_sp_temp/12;    //0-1000 /3-buf /4-1024
      HAL_GPIO_WritePin(led_2t_m_GPIO_Port,led_2t_m_Pin,GPIO_PIN_SET);
    }
    if (HAL_GPIO_ReadPin(DI_92_S20_m_GPIO_Port,DI_92_S20_m_Pin)==GPIO_PIN_SET)
    {
      feed_speed_sp=Feed_Fast_SP;    //0-1000 /3-buf /4-1024/ 10- 100
    }
    //----------------------------------------//

    // gripe instrument
    if ((HAL_GPIO_ReadPin(S11Gripe_GPIO_Port,S11Gripe_Pin)==GPIO_PIN_SET)&&(M1_motion==0)&&(feed_motion==0))
    {
      HAL_GPIO_WritePin(DO_51_K6_GPIO_Port,DO_51_K6_Pin,GPIO_PIN_RESET);
    } else{
      HAL_GPIO_WritePin(DO_51_K6_GPIO_Port,DO_51_K6_Pin,GPIO_PIN_SET);
    }
    if ((HAL_GPIO_ReadPin(S12ungrip_GPIO_Port,S12ungrip_Pin)==GPIO_PIN_SET)&&(M1_motion==0)&&(feed_motion==0))
    {
      HAL_GPIO_WritePin(DO_63_K7_GPIO_Port,DO_63_K7_Pin,GPIO_PIN_RESET);
    } else{
      HAL_GPIO_WritePin(DO_63_K7_GPIO_Port,DO_63_K7_Pin,GPIO_PIN_SET);
    }
    //----------------------------------------//

    // M1 on off, rocking motion
    M1_on.pos_previous=M1_on.pos_current;
    M1_on.pos_current=HAL_GPIO_ReadPin(DI_34_S7_m_GPIO_Port,DI_34_S7_m_Pin);
    if ((HAL_GPIO_ReadPin(S6Gearbox_GPIO_Port,S6Gearbox_Pin)==GPIO_PIN_SET)&&error_my==0)
    {

      if ((M1_on.pos_previous==GPIO_PIN_SET)&&(M1_on.pos_current==GPIO_PIN_RESET)&&(M1_motion==0))
      {
        if (HAL_GPIO_ReadPin(DI_34_S8_m_GPIO_Port,DI_34_S8_m_Pin)==GPIO_PIN_SET){
          M1_motion=1;
        } else{
          M1_motion=2;
        }
      }
    }

    Rocking_btn.pos_previous=Rocking_btn.pos_current;
    Rocking_btn.pos_current=HAL_GPIO_ReadPin(S2rocking_GPIO_Port,S2rocking_Pin);
    if ((Rocking_btn.pos_previous==GPIO_PIN_SET)&&(Rocking_btn.pos_current==GPIO_PIN_RESET)&&(error_my==0)&&(M1_motion==0))
    {
      M1_motion=3;  // zero when over (time based)
    }
    M1_off.pos_previous=M1_off.pos_current;
    M1_off.pos_current=HAL_GPIO_ReadPin(DI_29_S5_m_GPIO_Port,DI_29_S5_m_Pin);
    if ((M1_off.pos_previous==GPIO_PIN_SET)&&(M1_off.pos_current==GPIO_PIN_RESET)&&(M1_motion==1||M1_motion==2))
    {
      M1_motion=4;
    }
    //----------------------------------------//

    // pumps xyiamps error blocks everithyng
    if (error_my==0){

      if (oil_pump_state!=0)
      {
        HAL_GPIO_WritePin(Q2_GPIO_Port,Q2_Pin,GPIO_PIN_RESET);
        HAL_GPIO_WritePin(led_oil_GPIO_Port,led_oil_Pin,GPIO_PIN_RESET);
      }else{
        oil_pump_state=0;
        HAL_GPIO_WritePin(Q2_GPIO_Port,Q2_Pin,GPIO_PIN_SET);
        HAL_GPIO_WritePin(led_oil_GPIO_Port,led_oil_Pin,GPIO_PIN_SET);
      }
      //----------------------------------------//
      // coolant pump on
      if (HAL_GPIO_ReadPin(DI_63_S9_m_GPIO_Port,DI_63_S9_m_Pin)==GPIO_PIN_SET)
      {
        HAL_GPIO_WritePin(Q5_GPIO_Port,Q5_Pin,GPIO_PIN_RESET);
      } else {
        HAL_GPIO_WritePin(Q5_GPIO_Port,Q5_Pin,GPIO_PIN_SET);
      }
      //----------------------------------------//
      HAL_GPIO_WritePin(led_error_m_GPIO_Port,led_error_m_Pin, GPIO_PIN_SET);

    }else{
      M1_motion=0;
      feed_speed_sp=0;
      HAL_GPIO_WritePin(Q5_GPIO_Port,Q5_Pin,GPIO_PIN_SET);
      HAL_GPIO_WritePin(Q2_GPIO_Port,Q2_Pin,GPIO_PIN_SET);
      HAL_GPIO_WritePin(led_oil_GPIO_Port,led_oil_Pin,GPIO_PIN_SET);
      HAL_GPIO_WritePin(led_Temper_GPIO_Port,led_Temper_Pin, GPIO_PIN_SET);
      HAL_GPIO_WritePin(led_error_m_GPIO_Port,led_error_m_Pin, GPIO_PIN_RESET);
    }

    osDelay(50);  //20hz

    Deblock_btn.pos_previous=Deblock_btn.pos_current;
    Deblock_btn.pos_current=HAL_GPIO_ReadPin(DI_88_S16_m_GPIO_Port,DI_88_S16_m_Pin);
    if ((Deblock_btn.pos_previous==GPIO_PIN_SET)&&(Deblock_btn.pos_current==GPIO_PIN_RESET))
    {
      error_my=0;
    }

    //frequency check if interrupts not work and RPS less then 1 Reverse per/SEC motor max RPM 4000/60= 66 rps
    if ((TIM2->CNT)>10000)
    {
      TIM2->CNT=0;
      first_intrrupt=1;
    }
  }
  /* USER CODE END 5 */
}

void StartComunication(void *argument)
{
  /* USER CODE BEGIN StartComunication */
  uint8_t blynk=0,error_counter=0;
  unsigned char Ch232[100]={0};
  HAL_UART_StateTypeDef state_uart;
  /* Infinite loop */
  for(;;)
  {
    osDelay(100);
    blynk++;
    if ((error_my)&&(blynk>29))
    {
      if (blynk==30+5*error_counter)
      {
        HAL_GPIO_TogglePin(led_manual_GPIO_Port,led_manual_Pin);
        error_counter++;
      }
      if (error_my==error_counter/2)
      {
        HAL_GPIO_WritePin(led_manual_GPIO_Port,led_manual_Pin,GPIO_PIN_SET);
        error_counter=0;
      }
    }
    else {
      HAL_GPIO_WritePin(led_manual_GPIO_Port,led_manual_Pin,GPIO_PIN_SET);
    }
#if Comissioning==1
    state_uart=HAL_UART_GetState(&huart4);
    if (state_uart!=HAL_UART_STATE_BUSY_TX_RX&&state_uart!=HAL_UART_STATE_BUSY&&state_uart!=HAL_UART_STATE_BUSY_RX&&state_uart!=HAL_UART_STATE_BUSY_TX)
    {
      HAL_GPIO_WritePin(RE_DE_GPIO_Port,RE_DE_Pin,GPIO_PIN_SET); //transmit
      sprintf((char *)Ch232, "%s%d%s%d%s%d%s%d%s%d%s%d%s"," SP-", feed_speed_sp, " FRQ-", Freq_TIM2," IM4-", I_M4, " FdMtn-",feed_motion, "err-", error_my," Pol-",polyarity, "\r\n");
      HAL_UART_Transmit_DMA(&huart4,Ch232,100);
    }
#endif
  }
  /* USER CODE END StartComunication */
}

void StartFeed(void *argument)
{
  /* USER CODE BEGIN StartFeed */
  uint8_t startuem=0, M1_motion_prev=0,iter,feed_motion_prev=0;
  uint16_t i=0, Freqency;  //frequency 0-1000 -0 RPM 1000-4000 RPM
  int16_t errorsold1[200]={0};
  int16_t  Error1;
  int32_t regD1=0,regP1=0,regI1=0,PID1;
  /* Infinite loop */
  for(;;)
  {
    //--rocking motion actually not rocking---//
    if ((M1_motion==3)&&(i<Roking_time)){
      HAL_GPIO_WritePin(Q8_GPIO_Port,Q8_Pin, GPIO_PIN_SET); //shunt
      HAL_GPIO_WritePin(Q4_GPIO_Port,Q4_Pin, GPIO_PIN_SET);
      HAL_GPIO_WritePin(Q3_GPIO_Port,Q3_Pin, GPIO_PIN_RESET);
      HAL_GPIO_WritePin(Q6_GPIO_Port,Q6_Pin, GPIO_PIN_SET);
      PWM_M1=1000-M1_start_PWM;
      i++;
    }else if((M1_motion==3)&&(i>=Roking_time))
    {
      HAL_GPIO_WritePin(Q4_GPIO_Port,Q4_Pin, GPIO_PIN_SET);
      HAL_GPIO_WritePin(Q3_GPIO_Port,Q3_Pin, GPIO_PIN_SET);
      HAL_GPIO_WritePin(Q6_GPIO_Port,Q6_Pin, GPIO_PIN_SET);
      HAL_GPIO_WritePin(Q8_GPIO_Port,Q8_Pin, GPIO_PIN_SET); //shunt
      PWM_M1=1000;
      M1_motion=0;
      i=0;
    }
    //----------------------------------------//

    //---M1 left right------------------------//
    if (M1_motion==1&&M1_motion_prev==0) //right
    {
      i=0;
      PWM_M1=1000;
      HAL_GPIO_WritePin(Q4_GPIO_Port,Q4_Pin, GPIO_PIN_SET);
      HAL_GPIO_WritePin(Q3_GPIO_Port,Q3_Pin, GPIO_PIN_RESET);
      HAL_GPIO_WritePin(Q6_GPIO_Port,Q6_Pin, GPIO_PIN_SET);
      startuem=1;
    }
    if (M1_motion==2&&M1_motion_prev==0)  //left
    {
      i=0;
      PWM_M1=1000;
      HAL_GPIO_WritePin(Q4_GPIO_Port,Q4_Pin, GPIO_PIN_RESET);
      HAL_GPIO_WritePin(Q3_GPIO_Port,Q3_Pin, GPIO_PIN_SET);
      HAL_GPIO_WritePin(Q6_GPIO_Port,Q6_Pin, GPIO_PIN_SET);
      startuem=1;
    }
    if(startuem==1&&i<Acceleration_time)
    {

      PWM_M1=1000-M1_start_PWM-(600/Acceleration_time)*i;  //max 90%
      i++;
    }else if(startuem==1&&i>=Acceleration_time) {
      i=0;
      PWM_M1=0;
      startuem=0;
      HAL_GPIO_WritePin(Q8_GPIO_Port,Q8_Pin, GPIO_PIN_RESET); //shunt
    }
    //----------------------------------------//

    //---M1 brake------------------------//
    if ((M1_motion_prev==1||M1_motion_prev==2)&&M1_motion==4)
    {
      i=0;
      PWM_M1=1000;
      HAL_GPIO_WritePin(Q4_GPIO_Port,Q4_Pin, GPIO_PIN_SET);
      HAL_GPIO_WritePin(Q3_GPIO_Port,Q3_Pin, GPIO_PIN_SET);
      HAL_GPIO_WritePin(Q8_GPIO_Port,Q8_Pin, GPIO_PIN_SET); //shunt
    }
    if (M1_motion==4&&i<Brake_time)
    {
      HAL_GPIO_WritePin(Q6_GPIO_Port,Q6_Pin, GPIO_PIN_RESET);
      i++;
    }else if((M1_motion==4)&&(i>=Brake_time))
    {
      HAL_GPIO_WritePin(Q6_GPIO_Port,Q6_Pin, GPIO_PIN_SET);
      i=0;
      M1_motion=0;
    }
    //----------------------------------------//

    //----------NA VSYAKII SLYCHAI---------//
    if (M1_motion==0)
    {
      i=0;
      PWM_M1=1000;
      HAL_GPIO_WritePin(Q4_GPIO_Port,Q4_Pin, GPIO_PIN_SET);
      HAL_GPIO_WritePin(Q3_GPIO_Port,Q3_Pin, GPIO_PIN_SET);
      HAL_GPIO_WritePin(Q6_GPIO_Port,Q6_Pin, GPIO_PIN_SET);
      HAL_GPIO_WritePin(Q8_GPIO_Port,Q8_Pin, GPIO_PIN_SET); //shunt
      startuem=0;
    }
    //-------------------------------------//

    //-------------------------FEED-----------------------------//
    if (Freq_TIM2>10000){
      Freq_TIM2=10000;
    }else if (Freq_TIM2<130){
      error_my=6; //very hight frequency
    }
    Freqency=(uint16_t)(1000-Freq_TIM2/10); //os
    //enable
    if (feed_motion==0){
      HAL_GPIO_WritePin(Q7_GPIO_Port,Q7_Pin, GPIO_PIN_SET);
      if (feed_motion_prev!=0){
        for (iter=0; iter<199; iter++)
        {
          errorsold1[iter]=0;
        }
      }
    }else{
      HAL_GPIO_WritePin(Q7_GPIO_Port,Q7_Pin, GPIO_PIN_RESET);
      //-------------------pid1------------------------------------------//
      Error1=feed_speed_sp-Freqency;    //0-1000 zadanie 16-1003 feedback
      regI1=0;
      for (iter=0; iter<199; iter++)
      {
        regI1=regI1+errorsold1[iter];
      }
      regP1=Error1*P1;
      regI1 =(I1>0)? (regI1 + Error1)*I1:0;
      regD1=(Error1-errorsold1[0])*D1*20; //becouse dt is 0.05
      if (regD1<(-10000))
      {
        regD1=(-10000);
      }
      if (regD1>(10000))
      {
        regD1=(10000);
      }
      if (regI1<(-10000))
      {
        regI1=(-10000);
      }
      if (regI1>(10000))
      {
        regI1=(10000);
      }
      for (iter=198; iter>0; iter--)
      {
        errorsold1[iter+1]=errorsold1[iter];
      }
      errorsold1[0]=Error1;
      if ((Error1>=dead_zone1)||(dead_zone1==0)||(Error1<=(dead_zone1*(-1))) )
      {

        if (direct_pid==0){
          PID1=regP1+regI1+regD1;
        }else{
          PID1=(regP1+regI1+regD1)*(-1);
        }
        if (PID1<0)
        {
          PID1=0;
        }
        if (PID1>=10000)
        {
          PID1=10000;
        }
        if(I_M4<Hi_Current_lim)  //current limit
        {
          PWM_M4=1999-PID1/10; //output
        }else if((I_M4>=Hi_Current_lim)&&(PWM_M4<1990))
        {
          PWM_M4=PWM_M4+10;
        }

      }

      if (I_M4>Hi_Current_error){
        error_my=7; //very hight currnet
      }
      //---------------------------------------------------------//

    }

    if ((polyarity==1)&&(HAL_GPIO_ReadPin(tacho_dir_right_GPIO_Port,tacho_dir_right_Pin)==GPIO_PIN_SET)&&(I_M4>Rotation_lim))//left and actual right
    {
      error_my=8; //something wrong with direction left
    }
    if ((polyarity==0)&&(HAL_GPIO_ReadPin(tacho_dir_left_GPIO_Port,tacho_dir_left_Pin)==GPIO_PIN_SET)&&(I_M4>Rotation_lim))
    {
      error_my=9; //something wrong with direction right
    }

    //----------------------------------------------------------//
    osDelay(5);  //200 hz
    M1_motion_prev=M1_motion;
    feed_motion_prev=feed_motion;
  }

  /* USER CODE END StartFeed */
}

void HAL_TIM_PeriodElapsedCallback(TIM_HandleTypeDef *htim)
{
  if (htim->Instance == TIM6) {
    HAL_IncTick();
  }
}

void Error_Handler(void)
{
  __disable_irq();
  while (1)
  {
  }
}
